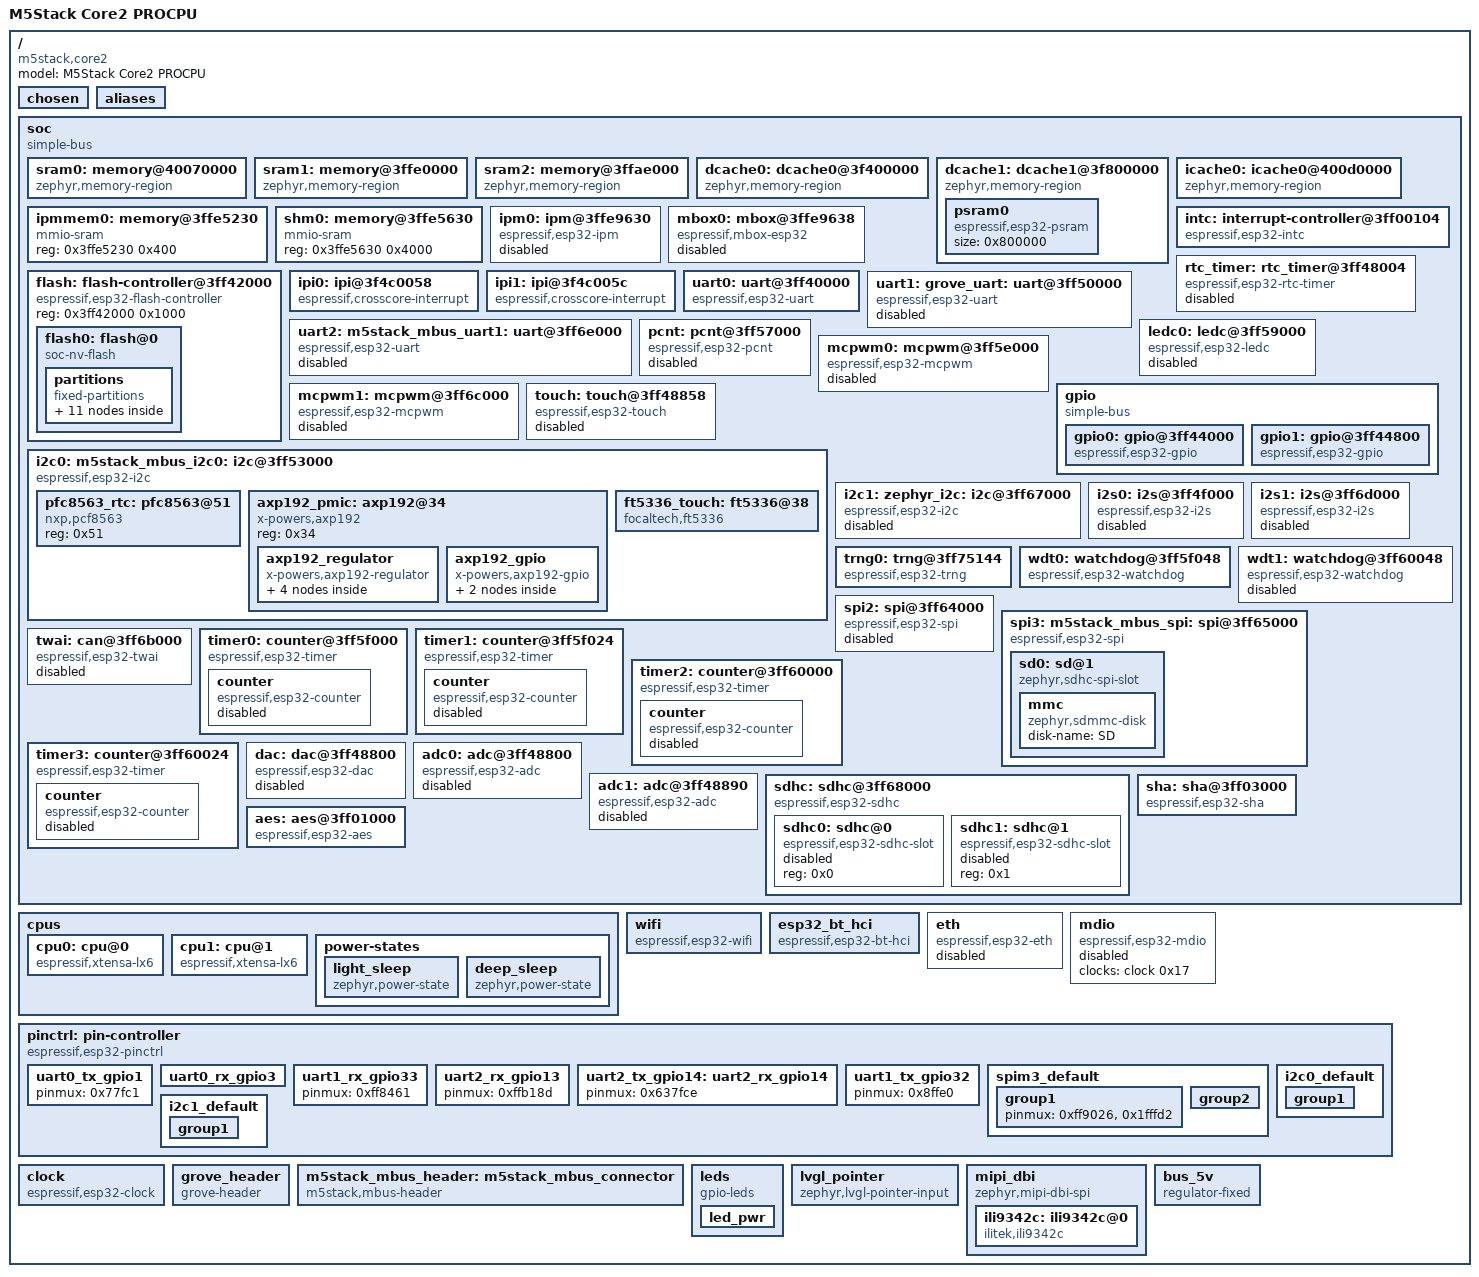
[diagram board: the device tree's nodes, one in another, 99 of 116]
/dts-v1/;

/* node '/' defined in zephyr/dts/common/skeleton.dtsi:9 */
/ {
	#address-cells = < 0x1 >;       /* in zephyr/dts/common/skeleton.dtsi:10 */
	#size-cells = < 0x1 >;          /* in zephyr/dts/common/skeleton.dtsi:11 */
	model = "M5Stack Core2 PROCPU"; /* in zephyr/boards/m5stack/m5stack_core2/m5stack_core2_procpu.dts:17 */
	compatible = "m5stack,core2";   /* in zephyr/boards/m5stack/m5stack_core2/m5stack_core2_procpu.dts:18 */

	/* node '/chosen' defined in zephyr/dts/common/skeleton.dtsi:13 */
	chosen {
		zephyr,canbus = &twai;                    /* in zephyr/dts/xtensa/espressif/esp32/esp32_common.dtsi:20 */
		zephyr,entropy = &trng0;                  /* in zephyr/dts/xtensa/espressif/esp32/esp32_common.dtsi:21 */
		zephyr,flash-controller = &flash;         /* in zephyr/dts/xtensa/espressif/esp32/esp32_common.dtsi:22 */
		zephyr,sram = &sram1;                     /* in zephyr/boards/m5stack/m5stack_core2/m5stack_core2_procpu.dts:31 */
		zephyr,console = &uart0;                  /* in zephyr/boards/m5stack/m5stack_core2/m5stack_core2_procpu.dts:32 */
		zephyr,shell-uart = &uart0;               /* in zephyr/boards/m5stack/m5stack_core2/m5stack_core2_procpu.dts:33 */
		zephyr,flash = &flash0;                   /* in zephyr/boards/m5stack/m5stack_core2/m5stack_core2_procpu.dts:34 */
		zephyr,display = &ili9342c;               /* in zephyr/boards/m5stack/m5stack_core2/m5stack_core2_procpu.dts:35 */
		zephyr,code-partition = &slot0_partition; /* in zephyr/boards/m5stack/m5stack_core2/m5stack_core2_procpu.dts:36 */
		zephyr,rtc = &pfc8563_rtc;                /* in zephyr/boards/m5stack/m5stack_core2/m5stack_core2_procpu.dts:37 */
		zephyr,bt-hci = &esp32_bt_hci;            /* in zephyr/boards/m5stack/m5stack_core2/m5stack_core2_procpu.dts:38 */
		zephyr,touch = &ft5336_touch;             /* in zephyr/boards/m5stack/m5stack_core2/m5stack_core2_procpu.dts:39 */
	};

	/* node '/aliases' defined in zephyr/dts/common/skeleton.dtsi:15 */
	aliases {
		pwr-led = &pwr_led; /* in zephyr/boards/m5stack/m5stack_core2/m5stack_core2_procpu.dts:21 */
		uart-0 = &uart0;    /* in zephyr/boards/m5stack/m5stack_core2/m5stack_core2_procpu.dts:22 */
		i2c-0 = &i2c0;      /* in zephyr/boards/m5stack/m5stack_core2/m5stack_core2_procpu.dts:23 */
		watchdog0 = &wdt0;  /* in zephyr/boards/m5stack/m5stack_core2/m5stack_core2_procpu.dts:24 */
		rtc = &pfc8563_rtc; /* in zephyr/boards/m5stack/m5stack_core2/m5stack_core2_procpu.dts:25 */
		led0 = &led_pwr;    /* in zephyr/boards/m5stack/m5stack_core2/m5stack_core2_procpu.dts:26 */
		sdhc0 = &sd0;       /* in zephyr/boards/m5stack/m5stack_core2/m5stack_core2_procpu.dts:27 */
	};

	/* node '/soc' defined in zephyr/dts/xtensa/xtensa.dtsi:10 */
	soc {
		#address-cells = < 0x1 >;  /* in zephyr/dts/xtensa/xtensa.dtsi:11 */
		#size-cells = < 0x1 >;     /* in zephyr/dts/xtensa/xtensa.dtsi:12 */
		compatible = "simple-bus"; /* in zephyr/dts/xtensa/xtensa.dtsi:13 */
		ranges;                    /* in zephyr/dts/xtensa/xtensa.dtsi:14 */

		/* node '/soc/memory@40070000' defined in zephyr/dts/xtensa/espressif/esp32/esp32_common.dtsi:106 */
		sram0: memory@40070000 {
			compatible = "zephyr,memory-region",
			             "mmio-sram";            /* in zephyr/dts/xtensa/espressif/esp32/esp32_common.dtsi:107 */
			reg = < 0x40070000 0x30000 >;        /* in zephyr/dts/xtensa/espressif/esp32/esp32_common.dtsi:108 */
			zephyr,memory-region = "SRAM0";      /* in zephyr/dts/xtensa/espressif/esp32/esp32_common.dtsi:109 */
		};

		/* node '/soc/memory@3ffe0000' defined in zephyr/dts/xtensa/espressif/esp32/esp32_common.dtsi:112 */
		sram1: memory@3ffe0000 {
			compatible = "zephyr,memory-region",
			             "mmio-sram";            /* in zephyr/dts/xtensa/espressif/esp32/esp32_common.dtsi:113 */
			reg = < 0x3ffe0000 0x20000 >;        /* in zephyr/dts/xtensa/espressif/esp32/esp32_common.dtsi:114 */
			zephyr,memory-region = "SRAM1";      /* in zephyr/dts/xtensa/espressif/esp32/esp32_common.dtsi:115 */
		};

		/* node '/soc/memory@3ffae000' defined in zephyr/dts/xtensa/espressif/esp32/esp32_common.dtsi:118 */
		sram2: memory@3ffae000 {
			compatible = "zephyr,memory-region",
			             "mmio-sram";            /* in zephyr/dts/xtensa/espressif/esp32/esp32_common.dtsi:119 */
			reg = < 0x3ffae000 0x32000 >;        /* in zephyr/dts/xtensa/espressif/esp32/esp32_common.dtsi:120 */
			zephyr,memory-region = "SRAM2";      /* in zephyr/dts/xtensa/espressif/esp32/esp32_common.dtsi:121 */
		};

		/* node '/soc/dcache0@3f400000' defined in zephyr/dts/xtensa/espressif/esp32/esp32_common.dtsi:124 */
		dcache0: dcache0@3f400000 {
			compatible = "zephyr,memory-region",
			             "mmio-sram";            /* in zephyr/dts/xtensa/espressif/esp32/esp32_common.dtsi:125 */
			reg = < 0x3f400000 0x400000 >;       /* in zephyr/dts/xtensa/espressif/esp32/esp32_common.dtsi:126 */
			zephyr,memory-region = "DCACHE0";    /* in zephyr/dts/xtensa/espressif/esp32/esp32_common.dtsi:127 */
		};

		/* node '/soc/dcache1@3f800000' defined in zephyr/dts/xtensa/espressif/esp32/esp32_common.dtsi:130 */
		dcache1: dcache1@3f800000 {
			compatible = "zephyr,memory-region",
			             "mmio-sram";            /* in zephyr/dts/xtensa/espressif/esp32/esp32_common.dtsi:131 */
			reg = < 0x3f800000 0x400000 >;       /* in zephyr/dts/xtensa/espressif/esp32/esp32_common.dtsi:132 */
			zephyr,memory-region = "DCACHE1";    /* in zephyr/dts/xtensa/espressif/esp32/esp32_common.dtsi:133 */

			/* node '/soc/dcache1@3f800000/psram0' defined in zephyr/dts/xtensa/espressif/esp32/esp32_common.dtsi:135 */
			psram0: psram0 {
				compatible = "espressif,esp32-psram"; /* in zephyr/dts/xtensa/espressif/esp32/esp32_common.dtsi:136 */
				size = < 0x800000 >;                  /* in zephyr/boards/m5stack/m5stack_core2/m5stack_core2_procpu.dts:91 */
			};
		};

		/* node '/soc/icache0@400d0000' defined in zephyr/dts/xtensa/espressif/esp32/esp32_common.dtsi:141 */
		icache0: icache0@400d0000 {
			compatible = "zephyr,memory-region",
			             "mmio-sram";            /* in zephyr/dts/xtensa/espressif/esp32/esp32_common.dtsi:142 */
			reg = < 0x400d0000 0xb30000 >;       /* in zephyr/dts/xtensa/espressif/esp32/esp32_common.dtsi:143 */
			zephyr,memory-region = "ICACHE0";    /* in zephyr/dts/xtensa/espressif/esp32/esp32_common.dtsi:144 */
		};

		/* node '/soc/memory@3ffe5230' defined in zephyr/dts/xtensa/espressif/esp32/esp32_common.dtsi:147 */
		ipmmem0: memory@3ffe5230 {
			compatible = "mmio-sram";   /* in zephyr/dts/xtensa/espressif/esp32/esp32_common.dtsi:148 */
			reg = < 0x3ffe5230 0x400 >; /* in zephyr/dts/xtensa/espressif/esp32/esp32_common.dtsi:149 */
			phandle = < 0x1 >;          /* in zephyr/dts/xtensa/espressif/esp32/esp32_common.dtsi:161 */
		};

		/* node '/soc/memory@3ffe5630' defined in zephyr/dts/xtensa/espressif/esp32/esp32_common.dtsi:152 */
		shm0: memory@3ffe5630 {
			compatible = "mmio-sram";    /* in zephyr/dts/xtensa/espressif/esp32/esp32_common.dtsi:153 */
			reg = < 0x3ffe5630 0x4000 >; /* in zephyr/dts/xtensa/espressif/esp32/esp32_common.dtsi:154 */
		};

		/* node '/soc/ipm@3ffe9630' defined in zephyr/dts/xtensa/espressif/esp32/esp32_common.dtsi:157 */
		ipm0: ipm@3ffe9630 {
			compatible = "espressif,esp32-ipm"; /* in zephyr/dts/xtensa/espressif/esp32/esp32_common.dtsi:158 */
			reg = < 0x3ffe9630 0x8 >;           /* in zephyr/dts/xtensa/espressif/esp32/esp32_common.dtsi:159 */
			status = "disabled";                /* in zephyr/dts/xtensa/espressif/esp32/esp32_common.dtsi:160 */
			shared-memory = < &ipmmem0 >;       /* in zephyr/dts/xtensa/espressif/esp32/esp32_common.dtsi:161 */
			shared-memory-size = < 0x400 >;     /* in zephyr/dts/xtensa/espressif/esp32/esp32_common.dtsi:162 */
			interrupts = < 0x18 0x0 0x0 >,
			             < 0x19 0x0 0x0 >;      /* in zephyr/dts/xtensa/espressif/esp32/esp32_common.dtsi:163 */
			interrupt-parent = < &intc >;       /* in zephyr/dts/xtensa/espressif/esp32/esp32_common.dtsi:165 */
		};

		/* node '/soc/mbox@3ffe9638' defined in zephyr/dts/xtensa/espressif/esp32/esp32_common.dtsi:168 */
		mbox0: mbox@3ffe9638 {
			compatible = "espressif,mbox-esp32"; /* in zephyr/dts/xtensa/espressif/esp32/esp32_common.dtsi:169 */
			reg = < 0x3ffe9638 0x8 >;            /* in zephyr/dts/xtensa/espressif/esp32/esp32_common.dtsi:170 */
			status = "disabled";                 /* in zephyr/dts/xtensa/espressif/esp32/esp32_common.dtsi:171 */
			shared-memory = < &ipmmem0 >;        /* in zephyr/dts/xtensa/espressif/esp32/esp32_common.dtsi:172 */
			shared-memory-size = < 0x400 >;      /* in zephyr/dts/xtensa/espressif/esp32/esp32_common.dtsi:173 */
			interrupts = < 0x18 0x0 0x0 >,
			             < 0x19 0x0 0x0 >;       /* in zephyr/dts/xtensa/espressif/esp32/esp32_common.dtsi:174 */
			interrupt-parent = < &intc >;        /* in zephyr/dts/xtensa/espressif/esp32/esp32_common.dtsi:176 */
			#mbox-cells = < 0x1 >;               /* in zephyr/dts/xtensa/espressif/esp32/esp32_common.dtsi:177 */
		};

		/* node '/soc/interrupt-controller@3ff00104' defined in zephyr/dts/xtensa/espressif/esp32/esp32_common.dtsi:180 */
		intc: interrupt-controller@3ff00104 {
			#interrupt-cells = < 0x3 >;          /* in zephyr/dts/xtensa/espressif/esp32/esp32_common.dtsi:181 */
			#address-cells = < 0x0 >;            /* in zephyr/dts/xtensa/espressif/esp32/esp32_common.dtsi:182 */
			compatible = "espressif,esp32-intc"; /* in zephyr/dts/xtensa/espressif/esp32/esp32_common.dtsi:183 */
			interrupt-controller;                /* in zephyr/dts/xtensa/espressif/esp32/esp32_common.dtsi:184 */
			reg = < 0x3ff00104 0x114 >;          /* in zephyr/dts/xtensa/espressif/esp32/esp32_common.dtsi:185 */
			status = "okay";                     /* in zephyr/dts/xtensa/espressif/esp32/esp32_common.dtsi:186 */
			phandle = < 0x2 >;                   /* in zephyr/dts/xtensa/espressif/esp32/esp32_common.dtsi:165 */
		};

		/* node '/soc/rtc_timer@3ff48004' defined in zephyr/dts/xtensa/espressif/esp32/esp32_common.dtsi:189 */
		rtc_timer: rtc_timer@3ff48004 {
			reg = < 0x3ff48004 0xc >;                 /* in zephyr/dts/xtensa/espressif/esp32/esp32_common.dtsi:190 */
			compatible = "espressif,esp32-rtc-timer"; /* in zephyr/dts/xtensa/espressif/esp32/esp32_common.dtsi:191 */
			clocks = < &clock 0x22 >;                 /* in zephyr/dts/xtensa/espressif/esp32/esp32_common.dtsi:192 */
			interrupts = < 0x2e 0x0 0x0 >;            /* in zephyr/dts/xtensa/espressif/esp32/esp32_common.dtsi:193 */
			interrupt-parent = < &intc >;             /* in zephyr/dts/xtensa/espressif/esp32/esp32_common.dtsi:194 */
			status = "disabled";                      /* in zephyr/dts/xtensa/espressif/esp32/esp32_common.dtsi:195 */
		};

		/* node '/soc/flash-controller@3ff42000' defined in zephyr/dts/xtensa/espressif/esp32/esp32_common.dtsi:198 */
		flash: flash-controller@3ff42000 {
			compatible = "espressif,esp32-flash-controller"; /* in zephyr/dts/xtensa/espressif/esp32/esp32_common.dtsi:199 */
			reg = < 0x3ff42000 0x1000 >;                     /* in zephyr/dts/xtensa/espressif/esp32/esp32_common.dtsi:200 */
			#address-cells = < 0x1 >;                        /* in zephyr/dts/xtensa/espressif/esp32/esp32_common.dtsi:201 */
			#size-cells = < 0x1 >;                           /* in zephyr/dts/xtensa/espressif/esp32/esp32_common.dtsi:202 */

			/* node '/soc/flash-controller@3ff42000/flash@0' defined in zephyr/dts/xtensa/espressif/esp32/esp32_common.dtsi:204 */
			flash0: flash@0 {
				compatible = "soc-nv-flash";   /* in zephyr/dts/xtensa/espressif/esp32/esp32_common.dtsi:205 */
				erase-block-size = < 0x1000 >; /* in zephyr/dts/xtensa/espressif/esp32/esp32_common.dtsi:206 */
				write-block-size = < 0x4 >;    /* in zephyr/dts/xtensa/espressif/esp32/esp32_common.dtsi:207 */
				reg = < 0x0 0x1000000 >;       /* in zephyr/boards/m5stack/m5stack_core2/m5stack_core2_procpu.dts:87 */

				/* node '/soc/flash-controller@3ff42000/flash@0/partitions' defined in zephyr/dts/vendor/espressif/partitions_0x1000_amp_4M.dtsi:8 */
				partitions {
					compatible = "fixed-partitions"; /* in zephyr/dts/vendor/espressif/partitions_0x1000_amp_4M.dtsi:9 */
					#address-cells = < 0x1 >;        /* in zephyr/dts/vendor/espressif/partitions_0x1000_amp_4M.dtsi:10 */
					#size-cells = < 0x1 >;           /* in zephyr/dts/vendor/espressif/partitions_0x1000_amp_4M.dtsi:11 */

					/* node '/soc/flash-controller@3ff42000/flash@0/partitions/partition@1000' defined in zephyr/dts/vendor/espressif/partitions_0x1000_amp_4M.dtsi:13 */
					boot_partition: partition@1000 {
						label = "mcuboot";       /* in zephyr/dts/vendor/espressif/partitions_0x1000_amp_4M.dtsi:14 */
						reg = < 0x1000 0xf000 >; /* in zephyr/dts/vendor/espressif/partitions_0x1000_amp_4M.dtsi:15 */
					};

					/* node '/soc/flash-controller@3ff42000/flash@0/partitions/partition@10000' defined in zephyr/dts/vendor/espressif/partitions_0x1000_amp_4M.dtsi:18 */
					sys_partition: partition@10000 {
						label = "sys";             /* in zephyr/dts/vendor/espressif/partitions_0x1000_amp_4M.dtsi:19 */
						reg = < 0x10000 0x10000 >; /* in zephyr/dts/vendor/espressif/partitions_0x1000_amp_4M.dtsi:20 */
					};

					/* node '/soc/flash-controller@3ff42000/flash@0/partitions/partition@20000' defined in zephyr/dts/vendor/espressif/partitions_0x1000_amp_4M.dtsi:23 */
					slot0_partition: partition@20000 {
						label = "image-0";          /* in zephyr/dts/vendor/espressif/partitions_0x1000_amp_4M.dtsi:24 */
						reg = < 0x20000 0x150000 >; /* in zephyr/dts/vendor/espressif/partitions_0x1000_amp_4M.dtsi:25 */
					};

					/* node '/soc/flash-controller@3ff42000/flash@0/partitions/partition@170000' defined in zephyr/dts/vendor/espressif/partitions_0x1000_amp_4M.dtsi:28 */
					slot1_partition: partition@170000 {
						label = "image-1";           /* in zephyr/dts/vendor/espressif/partitions_0x1000_amp_4M.dtsi:29 */
						reg = < 0x170000 0x150000 >; /* in zephyr/dts/vendor/espressif/partitions_0x1000_amp_4M.dtsi:30 */
					};

					/* node '/soc/flash-controller@3ff42000/flash@0/partitions/partition@2c0000' defined in zephyr/dts/vendor/espressif/partitions_0x1000_amp_4M.dtsi:33 */
					slot0_appcpu_partition: partition@2c0000 {
						label = "image-0-appcpu";   /* in zephyr/dts/vendor/espressif/partitions_0x1000_amp_4M.dtsi:34 */
						reg = < 0x2c0000 0x70000 >; /* in zephyr/dts/vendor/espressif/partitions_0x1000_amp_4M.dtsi:35 */
					};

					/* node '/soc/flash-controller@3ff42000/flash@0/partitions/partition@330000' defined in zephyr/dts/vendor/espressif/partitions_0x1000_amp_4M.dtsi:38 */
					slot1_appcpu_partition: partition@330000 {
						label = "image-1-appcpu";   /* in zephyr/dts/vendor/espressif/partitions_0x1000_amp_4M.dtsi:39 */
						reg = < 0x330000 0x70000 >; /* in zephyr/dts/vendor/espressif/partitions_0x1000_amp_4M.dtsi:40 */
					};

					/* node '/soc/flash-controller@3ff42000/flash@0/partitions/partition@3a0000' defined in zephyr/dts/vendor/espressif/partitions_0x1000_amp_4M.dtsi:43 */
					slot0_lpcore_partition: partition@3a0000 {
						label = "image-0-lpcore";  /* in zephyr/dts/vendor/espressif/partitions_0x1000_amp_4M.dtsi:44 */
						reg = < 0x3a0000 0x8000 >; /* in zephyr/dts/vendor/espressif/partitions_0x1000_amp_4M.dtsi:45 */
					};

					/* node '/soc/flash-controller@3ff42000/flash@0/partitions/partition@3a8000' defined in zephyr/dts/vendor/espressif/partitions_0x1000_amp_4M.dtsi:48 */
					slot1_lpcore_partition: partition@3a8000 {
						label = "image-1-lpcore";  /* in zephyr/dts/vendor/espressif/partitions_0x1000_amp_4M.dtsi:49 */
						reg = < 0x3a8000 0x8000 >; /* in zephyr/dts/vendor/espressif/partitions_0x1000_amp_4M.dtsi:50 */
					};

					/* node '/soc/flash-controller@3ff42000/flash@0/partitions/partition@3b0000' defined in zephyr/dts/vendor/espressif/partitions_0x1000_amp_4M.dtsi:53 */
					storage_partition: partition@3b0000 {
						label = "storage";          /* in zephyr/dts/vendor/espressif/partitions_0x1000_amp_4M.dtsi:54 */
						reg = < 0x3b0000 0x30000 >; /* in zephyr/dts/vendor/espressif/partitions_0x1000_amp_4M.dtsi:55 */
					};

					/* node '/soc/flash-controller@3ff42000/flash@0/partitions/partition@3e0000' defined in zephyr/dts/vendor/espressif/partitions_0x1000_amp_4M.dtsi:58 */
					scratch_partition: partition@3e0000 {
						label = "image-scratch";    /* in zephyr/dts/vendor/espressif/partitions_0x1000_amp_4M.dtsi:59 */
						reg = < 0x3e0000 0x1f000 >; /* in zephyr/dts/vendor/espressif/partitions_0x1000_amp_4M.dtsi:60 */
					};

					/* node '/soc/flash-controller@3ff42000/flash@0/partitions/partition@3ff000' defined in zephyr/dts/vendor/espressif/partitions_0x1000_amp_4M.dtsi:63 */
					coredump_partition: partition@3ff000 {
						label = "coredump";        /* in zephyr/dts/vendor/espressif/partitions_0x1000_amp_4M.dtsi:64 */
						reg = < 0x3ff000 0x1000 >; /* in zephyr/dts/vendor/espressif/partitions_0x1000_amp_4M.dtsi:65 */
					};
				};
			};
		};

		/* node '/soc/ipi@3f4c0058' defined in zephyr/dts/xtensa/espressif/esp32/esp32_common.dtsi:212 */
		ipi0: ipi@3f4c0058 {
			compatible = "espressif,crosscore-interrupt"; /* in zephyr/dts/xtensa/espressif/esp32/esp32_common.dtsi:213 */
			reg = < 0x3f4c0058 0x4 >;                     /* in zephyr/dts/xtensa/espressif/esp32/esp32_common.dtsi:214 */
			interrupts = < 0x18 0x0 0x0 >;                /* in zephyr/dts/xtensa/espressif/esp32/esp32_common.dtsi:215 */
			interrupt-parent = < &intc >;                 /* in zephyr/dts/xtensa/espressif/esp32/esp32_common.dtsi:216 */
		};

		/* node '/soc/ipi@3f4c005c' defined in zephyr/dts/xtensa/espressif/esp32/esp32_common.dtsi:219 */
		ipi1: ipi@3f4c005c {
			compatible = "espressif,crosscore-interrupt"; /* in zephyr/dts/xtensa/espressif/esp32/esp32_common.dtsi:220 */
			reg = < 0x3f4c005c 0x4 >;                     /* in zephyr/dts/xtensa/espressif/esp32/esp32_common.dtsi:221 */
			interrupts = < 0x19 0x0 0x0 >;                /* in zephyr/dts/xtensa/espressif/esp32/esp32_common.dtsi:222 */
			interrupt-parent = < &intc >;                 /* in zephyr/dts/xtensa/espressif/esp32/esp32_common.dtsi:223 */
		};

		/* node '/soc/uart@3ff40000' defined in zephyr/dts/xtensa/espressif/esp32/esp32_common.dtsi:226 */
		uart0: uart@3ff40000 {
			compatible = "espressif,esp32-uart";             /* in zephyr/dts/xtensa/espressif/esp32/esp32_common.dtsi:227 */
			reg = < 0x3ff40000 0x400 >;                      /* in zephyr/dts/xtensa/espressif/esp32/esp32_common.dtsi:228 */
			interrupts = < 0x22 0x0 0x0 >;                   /* in zephyr/dts/xtensa/espressif/esp32/esp32_common.dtsi:229 */
			interrupt-parent = < &intc >;                    /* in zephyr/dts/xtensa/espressif/esp32/esp32_common.dtsi:230 */
			clocks = < &clock 0x1 >;                         /* in zephyr/dts/xtensa/espressif/esp32/esp32_common.dtsi:231 */
			status = "okay";                                 /* in zephyr/boards/m5stack/m5stack_core2/m5stack_core2_procpu.dts:95 */
			current-speed = < 0x1c200 >;                     /* in zephyr/boards/m5stack/m5stack_core2/m5stack_core2_procpu.dts:96 */
			pinctrl-0 = < &uart0_tx_gpio1 &uart0_rx_gpio3 >; /* in zephyr/boards/m5stack/m5stack_core2/m5stack_core2_procpu.dts:97 */
			pinctrl-names = "default";                       /* in zephyr/boards/m5stack/m5stack_core2/m5stack_core2_procpu.dts:98 */
		};

		/* node '/soc/uart@3ff50000' defined in zephyr/dts/xtensa/espressif/esp32/esp32_common.dtsi:235 */
		uart1: grove_uart: m5stack_mbus_uart0: uart@3ff50000 {
			compatible = "espressif,esp32-uart";               /* in zephyr/dts/xtensa/espressif/esp32/esp32_common.dtsi:236 */
			reg = < 0x3ff50000 0x400 >;                        /* in zephyr/dts/xtensa/espressif/esp32/esp32_common.dtsi:237 */
			interrupts = < 0x23 0x0 0x0 >;                     /* in zephyr/dts/xtensa/espressif/esp32/esp32_common.dtsi:238 */
			interrupt-parent = < &intc >;                      /* in zephyr/dts/xtensa/espressif/esp32/esp32_common.dtsi:239 */
			clocks = < &clock 0x2 >;                           /* in zephyr/dts/xtensa/espressif/esp32/esp32_common.dtsi:240 */
			status = "disabled";                               /* in zephyr/boards/m5stack/m5stack_core2/m5stack_core2_procpu.dts:102 */
			current-speed = < 0x1c200 >;                       /* in zephyr/boards/m5stack/m5stack_core2/m5stack_core2_procpu.dts:103 */
			pinctrl-0 = < &uart1_rx_gpio33 &uart1_tx_gpio32 >; /* in zephyr/boards/m5stack/m5stack_core2/m5stack_core2_procpu.dts:104 */
			pinctrl-names = "default";                         /* in zephyr/boards/m5stack/m5stack_core2/m5stack_core2_procpu.dts:105 */
		};

		/* node '/soc/uart@3ff6e000' defined in zephyr/dts/xtensa/espressif/esp32/esp32_common.dtsi:244 */
		uart2: m5stack_mbus_uart1: uart@3ff6e000 {
			compatible = "espressif,esp32-uart"; /* in zephyr/dts/xtensa/espressif/esp32/esp32_common.dtsi:245 */
			reg = < 0x3ff6e000 0x400 >;          /* in zephyr/dts/xtensa/espressif/esp32/esp32_common.dtsi:246 */
			interrupts = < 0x24 0x0 0x0 >;       /* in zephyr/dts/xtensa/espressif/esp32/esp32_common.dtsi:247 */
			interrupt-parent = < &intc >;        /* in zephyr/dts/xtensa/espressif/esp32/esp32_common.dtsi:248 */
			clocks = < &clock 0x3 >;             /* in zephyr/dts/xtensa/espressif/esp32/esp32_common.dtsi:249 */
			status = "disabled";                 /* in zephyr/dts/xtensa/espressif/esp32/esp32_common.dtsi:250 */
		};

		/* node '/soc/pcnt@3ff57000' defined in zephyr/dts/xtensa/espressif/esp32/esp32_common.dtsi:253 */
		pcnt: pcnt@3ff57000 {
			compatible = "espressif,esp32-pcnt"; /* in zephyr/dts/xtensa/espressif/esp32/esp32_common.dtsi:254 */
			reg = < 0x3ff57000 0x1000 >;         /* in zephyr/dts/xtensa/espressif/esp32/esp32_common.dtsi:255 */
			interrupts = < 0x30 0x0 0x0 >;       /* in zephyr/dts/xtensa/espressif/esp32/esp32_common.dtsi:256 */
			interrupt-parent = < &intc >;        /* in zephyr/dts/xtensa/espressif/esp32/esp32_common.dtsi:257 */
			clocks = < &clock 0xf >;             /* in zephyr/dts/xtensa/espressif/esp32/esp32_common.dtsi:258 */
			status = "disabled";                 /* in zephyr/dts/xtensa/espressif/esp32/esp32_common.dtsi:259 */
		};

		/* node '/soc/ledc@3ff59000' defined in zephyr/dts/xtensa/espressif/esp32/esp32_common.dtsi:262 */
		ledc0: ledc@3ff59000 {
			compatible = "espressif,esp32-ledc"; /* in zephyr/dts/xtensa/espressif/esp32/esp32_common.dtsi:263 */
			#pwm-cells = < 0x3 >;                /* in zephyr/dts/xtensa/espressif/esp32/esp32_common.dtsi:264 */
			reg = < 0x3ff59000 0x800 >;          /* in zephyr/dts/xtensa/espressif/esp32/esp32_common.dtsi:265 */
			clocks = < &clock 0x0 >;             /* in zephyr/dts/xtensa/espressif/esp32/esp32_common.dtsi:266 */
			status = "disabled";                 /* in zephyr/dts/xtensa/espressif/esp32/esp32_common.dtsi:267 */
		};

		/* node '/soc/mcpwm@3ff5e000' defined in zephyr/dts/xtensa/espressif/esp32/esp32_common.dtsi:270 */
		mcpwm0: mcpwm@3ff5e000 {
			compatible = "espressif,esp32-mcpwm"; /* in zephyr/dts/xtensa/espressif/esp32/esp32_common.dtsi:271 */
			reg = < 0x3ff5e000 0x1000 >;          /* in zephyr/dts/xtensa/espressif/esp32/esp32_common.dtsi:272 */
			interrupts = < 0x27 0x0 0x0 >;        /* in zephyr/dts/xtensa/espressif/esp32/esp32_common.dtsi:273 */
			interrupt-parent = < &intc >;         /* in zephyr/dts/xtensa/espressif/esp32/esp32_common.dtsi:274 */
			clocks = < &clock 0xa >;              /* in zephyr/dts/xtensa/espressif/esp32/esp32_common.dtsi:275 */
			#pwm-cells = < 0x3 >;                 /* in zephyr/dts/xtensa/espressif/esp32/esp32_common.dtsi:276 */
			status = "disabled";                  /* in zephyr/dts/xtensa/espressif/esp32/esp32_common.dtsi:277 */
		};

		/* node '/soc/mcpwm@3ff6c000' defined in zephyr/dts/xtensa/espressif/esp32/esp32_common.dtsi:280 */
		mcpwm1: mcpwm@3ff6c000 {
			compatible = "espressif,esp32-mcpwm"; /* in zephyr/dts/xtensa/espressif/esp32/esp32_common.dtsi:281 */
			reg = < 0x3ff6c000 0x1000 >;          /* in zephyr/dts/xtensa/espressif/esp32/esp32_common.dtsi:282 */
			interrupts = < 0x28 0x0 0x0 >;        /* in zephyr/dts/xtensa/espressif/esp32/esp32_common.dtsi:283 */
			interrupt-parent = < &intc >;         /* in zephyr/dts/xtensa/espressif/esp32/esp32_common.dtsi:284 */
			clocks = < &clock 0xb >;              /* in zephyr/dts/xtensa/espressif/esp32/esp32_common.dtsi:285 */
			#pwm-cells = < 0x3 >;                 /* in zephyr/dts/xtensa/espressif/esp32/esp32_common.dtsi:286 */
			status = "disabled";                  /* in zephyr/dts/xtensa/espressif/esp32/esp32_common.dtsi:287 */
		};

		/* node '/soc/gpio' defined in zephyr/dts/xtensa/espressif/esp32/esp32_common.dtsi:290 */
		gpio: gpio {
			compatible = "simple-bus";                                     /* in zephyr/dts/xtensa/espressif/esp32/esp32_common.dtsi:291 */
			gpio-map-mask = < 0xffffffe0 0xffffffc0 >;                     /* in zephyr/dts/xtensa/espressif/esp32/esp32_common.dtsi:292 */
			gpio-map-pass-thru = < 0x1f 0x3f >;                            /* in zephyr/dts/xtensa/espressif/esp32/esp32_common.dtsi:293 */
			gpio-map = < 0x0 0x0 &gpio0 0x0 0x0 0x20 0x0 &gpio1 0x0 0x0 >; /* in zephyr/dts/xtensa/espressif/esp32/esp32_common.dtsi:294 */
			#gpio-cells = < 0x2 >;                                         /* in zephyr/dts/xtensa/espressif/esp32/esp32_common.dtsi:296 */
			#address-cells = < 0x1 >;                                      /* in zephyr/dts/xtensa/espressif/esp32/esp32_common.dtsi:297 */
			#size-cells = < 0x1 >;                                         /* in zephyr/dts/xtensa/espressif/esp32/esp32_common.dtsi:298 */
			ranges;                                                        /* in zephyr/dts/xtensa/espressif/esp32/esp32_common.dtsi:299 */

			/* node '/soc/gpio/gpio@3ff44000' defined in zephyr/dts/xtensa/espressif/esp32/esp32_common.dtsi:301 */
			gpio0: gpio@3ff44000 {
				compatible = "espressif,esp32-gpio"; /* in zephyr/dts/xtensa/espressif/esp32/esp32_common.dtsi:302 */
				gpio-controller;                     /* in zephyr/dts/xtensa/espressif/esp32/esp32_common.dtsi:303 */
				#gpio-cells = < 0x2 >;               /* in zephyr/dts/xtensa/espressif/esp32/esp32_common.dtsi:304 */
				reg = < 0x3ff44000 0x800 >;          /* in zephyr/dts/xtensa/espressif/esp32/esp32_common.dtsi:305 */
				interrupts = < 0x16 0x0 0x0 >;       /* in zephyr/dts/xtensa/espressif/esp32/esp32_common.dtsi:306 */
				interrupt-parent = < &intc >;        /* in zephyr/dts/xtensa/espressif/esp32/esp32_common.dtsi:307 */
				ngpios = < 0x20 >;                   /* in zephyr/dts/xtensa/espressif/esp32/esp32_common.dtsi:313 */
				gpio-reserved-ranges = < 0x14 0x1 >,
				                       < 0x18 0x1 >,
				                       < 0x1c 0x4 >; /* in zephyr/dts/xtensa/espressif/esp32/esp32_d0wd_v3.dtsi:11 */
				status = "okay";                     /* in zephyr/boards/m5stack/m5stack_core2/m5stack_core2_procpu.dts:109 */
				phandle = < 0x8 >;                   /* in zephyr/dts/xtensa/espressif/esp32/esp32_common.dtsi:294 */
			};

			/* node '/soc/gpio/gpio@3ff44800' defined in zephyr/dts/xtensa/espressif/esp32/esp32_common.dtsi:316 */
			gpio1: gpio@3ff44800 {
				compatible = "espressif,esp32-gpio"; /* in zephyr/dts/xtensa/espressif/esp32/esp32_common.dtsi:317 */
				gpio-controller;                     /* in zephyr/dts/xtensa/espressif/esp32/esp32_common.dtsi:318 */
				#gpio-cells = < 0x2 >;               /* in zephyr/dts/xtensa/espressif/esp32/esp32_common.dtsi:319 */
				reg = < 0x3ff44800 0x800 >;          /* in zephyr/dts/xtensa/espressif/esp32/esp32_common.dtsi:320 */
				interrupts = < 0x16 0x0 0x0 >;       /* in zephyr/dts/xtensa/espressif/esp32/esp32_common.dtsi:321 */
				interrupt-parent = < &intc >;        /* in zephyr/dts/xtensa/espressif/esp32/esp32_common.dtsi:322 */
				ngpios = < 0x8 >;                    /* in zephyr/dts/xtensa/espressif/esp32/esp32_common.dtsi:323 */
				status = "okay";                     /* in zephyr/boards/m5stack/m5stack_core2/m5stack_core2_procpu.dts:113 */
				phandle = < 0x9 >;                   /* in zephyr/dts/xtensa/espressif/esp32/esp32_common.dtsi:294 */
			};
		};

		/* node '/soc/touch@3ff48858' defined in zephyr/dts/xtensa/espressif/esp32/esp32_common.dtsi:327 */
		touch: touch@3ff48858 {
			compatible = "espressif,esp32-touch"; /* in zephyr/dts/xtensa/espressif/esp32/esp32_common.dtsi:328 */
			reg = < 0x3ff48858 0x38 >;            /* in zephyr/dts/xtensa/espressif/esp32/esp32_common.dtsi:329 */
			interrupts = < 0x2e 0x0 0x0 >;        /* in zephyr/dts/xtensa/espressif/esp32/esp32_common.dtsi:330 */
			interrupt-parent = < &intc >;         /* in zephyr/dts/xtensa/espressif/esp32/esp32_common.dtsi:331 */
			status = "disabled";                  /* in zephyr/dts/xtensa/espressif/esp32/esp32_common.dtsi:332 */
		};

		/* node '/soc/i2c@3ff53000' defined in zephyr/dts/xtensa/espressif/esp32/esp32_common.dtsi:335 */
		i2c0: m5stack_mbus_i2c0: i2c@3ff53000 {
			compatible = "espressif,esp32-i2c"; /* in zephyr/dts/xtensa/espressif/esp32/esp32_common.dtsi:336 */
			#address-cells = < 0x1 >;           /* in zephyr/dts/xtensa/espressif/esp32/esp32_common.dtsi:337 */
			#size-cells = < 0x0 >;              /* in zephyr/dts/xtensa/espressif/esp32/esp32_common.dtsi:338 */
			reg = < 0x3ff53000 0x1000 >;        /* in zephyr/dts/xtensa/espressif/esp32/esp32_common.dtsi:339 */
			interrupts = < 0x31 0x0 0x0 >;      /* in zephyr/dts/xtensa/espressif/esp32/esp32_common.dtsi:340 */
			interrupt-parent = < &intc >;       /* in zephyr/dts/xtensa/espressif/esp32/esp32_common.dtsi:341 */
			clocks = < &clock 0x4 >;            /* in zephyr/dts/xtensa/espressif/esp32/esp32_common.dtsi:342 */
			status = "okay";                    /* in zephyr/boards/m5stack/m5stack_core2/m5stack_core2_procpu.dts:117 */
			clock-frequency = < 0x61a80 >;      /* in zephyr/boards/m5stack/m5stack_core2/m5stack_core2_procpu.dts:118 */
			sda-gpios = < &gpio0 0x15 0x6 >;    /* in zephyr/boards/m5stack/m5stack_core2/m5stack_core2_procpu.dts:119 */
			scl-gpios = < &gpio0 0x16 0x6 >;    /* in zephyr/boards/m5stack/m5stack_core2/m5stack_core2_procpu.dts:120 */
			pinctrl-0 = < &i2c0_default >;      /* in zephyr/boards/m5stack/m5stack_core2/m5stack_core2_procpu.dts:121 */
			scl-timeout-us = < 0x0 >;           /* in zephyr/boards/m5stack/m5stack_core2/m5stack_core2_procpu.dts:122 */
			pinctrl-names = "default";          /* in zephyr/boards/m5stack/m5stack_core2/m5stack_core2_procpu.dts:123 */

			/* node '/soc/i2c@3ff53000/pfc8563@51' defined in zephyr/boards/m5stack/m5stack_core2/m5stack_core2_procpu.dts:125 */
			pfc8563_rtc: pfc8563@51 {
				compatible = "nxp,pcf8563"; /* in zephyr/boards/m5stack/m5stack_core2/m5stack_core2_procpu.dts:126 */
				reg = < 0x51 >;             /* in zephyr/boards/m5stack/m5stack_core2/m5stack_core2_procpu.dts:127 */
				status = "okay";            /* in zephyr/boards/m5stack/m5stack_core2/m5stack_core2_procpu.dts:128 */
			};

			/* node '/soc/i2c@3ff53000/axp192@34' defined in zephyr/boards/m5stack/m5stack_core2/m5stack_core2_procpu.dts:131 */
			axp192_pmic: axp192@34 {
				compatible = "x-powers,axp192"; /* in zephyr/boards/m5stack/m5stack_core2/m5stack_core2_procpu.dts:132 */
				reg = < 0x34 >;                 /* in zephyr/boards/m5stack/m5stack_core2/m5stack_core2_procpu.dts:133 */
				status = "okay";                /* in zephyr/boards/m5stack/m5stack_core2/m5stack_core2_procpu.dts:134 */

				/* node '/soc/i2c@3ff53000/axp192@34/axp192_regulator' defined in zephyr/boards/m5stack/m5stack_core2/m5stack_core2_procpu.dts:136 */
				axp192_regulator: axp192_regulator {
					compatible = "x-powers,axp192-regulator"; /* in zephyr/boards/m5stack/m5stack_core2/m5stack_core2_procpu.dts:137 */
					status = "okay";                          /* in zephyr/boards/m5stack/m5stack_core2/m5stack_core2_procpu.dts:138 */

					/* node '/soc/i2c@3ff53000/axp192@34/axp192_regulator/DCDC1' defined in zephyr/boards/m5stack/m5stack_core2/m5stack_core2_procpu.dts:140 */
					vdd_mcu: DCDC1 {
						regulator-init-microvolt = < 0x331df0 >; /* in zephyr/boards/m5stack/m5stack_core2/m5stack_core2_procpu.dts:141 */
						regulator-min-microvolt = < 0x30d400 >;  /* in zephyr/boards/m5stack/m5stack_core2/m5stack_core2_procpu.dts:142 */
						regulator-max-microvolt = < 0x33e140 >;  /* in zephyr/boards/m5stack/m5stack_core2/m5stack_core2_procpu.dts:143 */
						regulator-initial-mode = < 0x0 >;        /* in zephyr/boards/m5stack/m5stack_core2/m5stack_core2_procpu.dts:144 */
						regulator-boot-on;                       /* in zephyr/boards/m5stack/m5stack_core2/m5stack_core2_procpu.dts:145 */
						regulator-always-on;                     /* in zephyr/boards/m5stack/m5stack_core2/m5stack_core2_procpu.dts:146 */
					};

					/* node '/soc/i2c@3ff53000/axp192@34/axp192_regulator/DCDC3' defined in zephyr/boards/m5stack/m5stack_core2/m5stack_core2_procpu.dts:149 */
					lcd_bg: DCDC3 {
						regulator-init-microvolt = < 0x2ab980 >; /* in zephyr/boards/m5stack/m5stack_core2/m5stack_core2_procpu.dts:150 */
						regulator-min-microvolt = < 0x2625a0 >;  /* in zephyr/boards/m5stack/m5stack_core2/m5stack_core2_procpu.dts:151 */
						regulator-max-microvolt = < 0x325aa0 >;  /* in zephyr/boards/m5stack/m5stack_core2/m5stack_core2_procpu.dts:152 */
						regulator-boot-on;                       /* in zephyr/boards/m5stack/m5stack_core2/m5stack_core2_procpu.dts:153 */
						phandle = < 0x12 >;                      /* in zephyr/boards/m5stack/m5stack_core2/m5stack_core2_procpu.dts:70 */
					};

					/* node '/soc/i2c@3ff53000/axp192@34/axp192_regulator/LDO2' defined in zephyr/boards/m5stack/m5stack_core2/m5stack_core2_procpu.dts:156 */
					v_peri: LDO2 {
						regulator-init-microvolt = < 0x325aa0 >; /* in zephyr/boards/m5stack/m5stack_core2/m5stack_core2_procpu.dts:157 */
						regulator-min-microvolt = < 0x30d400 >;  /* in zephyr/boards/m5stack/m5stack_core2/m5stack_core2_procpu.dts:158 */
						regulator-max-microvolt = < 0x325aa0 >;  /* in zephyr/boards/m5stack/m5stack_core2/m5stack_core2_procpu.dts:159 */
						regulator-boot-on;                       /* in zephyr/boards/m5stack/m5stack_core2/m5stack_core2_procpu.dts:160 */
					};

					/* node '/soc/i2c@3ff53000/axp192@34/axp192_regulator/LDO3' defined in zephyr/boards/m5stack/m5stack_core2/m5stack_core2_procpu.dts:163 */
					vib_motor: LDO3 {
						regulator-init-microvolt = < 0x2ab980 >; /* in zephyr/boards/m5stack/m5stack_core2/m5stack_core2_procpu.dts:164 */
					};
				};

				/* node '/soc/i2c@3ff53000/axp192@34/axp192_gpio' defined in zephyr/boards/m5stack/m5stack_core2/m5stack_core2_procpu.dts:168 */
				axp192_gpio: axp192_gpio {
					compatible = "x-powers,axp192-gpio"; /* in zephyr/boards/m5stack/m5stack_core2/m5stack_core2_procpu.dts:169 */
					gpio-controller;                     /* in zephyr/boards/m5stack/m5stack_core2/m5stack_core2_procpu.dts:170 */
					#gpio-cells = < 0x2 >;               /* in zephyr/boards/m5stack/m5stack_core2/m5stack_core2_procpu.dts:171 */
					ngpios = < 0x6 >;                    /* in zephyr/boards/m5stack/m5stack_core2/m5stack_core2_procpu.dts:172 */
					status = "okay";                     /* in zephyr/boards/m5stack/m5stack_core2/m5stack_core2_procpu.dts:173 */
					phandle = < 0xf >;                   /* in zephyr/boards/m5stack/m5stack_core2/m5stack_core2_procpu.dts:46 */

					/* node '/soc/i2c@3ff53000/axp192@34/axp192_gpio/axp192_gpio1' defined in zephyr/boards/m5stack/m5stack_core2/m5stack_core2_procpu.dts:175 */
					pwr_led: axp192_gpio1 {
						gpio-hog;              /* in zephyr/boards/m5stack/m5stack_core2/m5stack_core2_procpu.dts:176 */
						gpios = < 0x1 0x7 >;   /* in zephyr/boards/m5stack/m5stack_core2/m5stack_core2_procpu.dts:177 */
						output-high;           /* in zephyr/boards/m5stack/m5stack_core2/m5stack_core2_procpu.dts:178 */
						line-name = "pwr-led"; /* in zephyr/boards/m5stack/m5stack_core2/m5stack_core2_procpu.dts:179 */
					};

					/* node '/soc/i2c@3ff53000/axp192@34/axp192_gpio/axp192_gpio0' defined in zephyr/boards/m5stack/m5stack_core2/m5stack_core2_procpu.dts:182 */
					bus_pwr_en: axp192_gpio0 {
						gpio-hog;                 /* in zephyr/boards/m5stack/m5stack_core2/m5stack_core2_procpu.dts:183 */
						gpios = < 0x0 0x0 >;      /* in zephyr/boards/m5stack/m5stack_core2/m5stack_core2_procpu.dts:184 */
						output-high;              /* in zephyr/boards/m5stack/m5stack_core2/m5stack_core2_procpu.dts:185 */
						line-name = "bus_pwr_en"; /* in zephyr/boards/m5stack/m5stack_core2/m5stack_core2_procpu.dts:186 */
					};
				};
			};

			/* node '/soc/i2c@3ff53000/ft5336@38' defined in zephyr/boards/m5stack/m5stack_core2/m5stack_core2_procpu.dts:191 */
			ft5336_touch: ft5336@38 {
				compatible = "focaltech,ft5336"; /* in zephyr/boards/m5stack/m5stack_core2/m5stack_core2_procpu.dts:192 */
				reg = < 0x38 >;                  /* in zephyr/boards/m5stack/m5stack_core2/m5stack_core2_procpu.dts:193 */
				int-gpios = < &gpio1 0x7 0x1 >;  /* in zephyr/boards/m5stack/m5stack_core2/m5stack_core2_procpu.dts:194 */
				phandle = < 0x10 >;              /* in zephyr/boards/m5stack/m5stack_core2/m5stack_core2_procpu.dts:53 */
			};
		};

		/* node '/soc/i2c@3ff67000' defined in zephyr/dts/xtensa/espressif/esp32/esp32_common.dtsi:346 */
		i2c1: zephyr_i2c: m5stack_mbus_i2c1: i2c@3ff67000 {
			compatible = "espressif,esp32-i2c"; /* in zephyr/dts/xtensa/espressif/esp32/esp32_common.dtsi:347 */
			#address-cells = < 0x1 >;           /* in zephyr/dts/xtensa/espressif/esp32/esp32_common.dtsi:348 */
			#size-cells = < 0x0 >;              /* in zephyr/dts/xtensa/espressif/esp32/esp32_common.dtsi:349 */
			reg = < 0x3ff67000 0x1000 >;        /* in zephyr/dts/xtensa/espressif/esp32/esp32_common.dtsi:350 */
			interrupts = < 0x32 0x0 0x0 >;      /* in zephyr/dts/xtensa/espressif/esp32/esp32_common.dtsi:351 */
			interrupt-parent = < &intc >;       /* in zephyr/dts/xtensa/espressif/esp32/esp32_common.dtsi:352 */
			clocks = < &clock 0x5 >;            /* in zephyr/dts/xtensa/espressif/esp32/esp32_common.dtsi:353 */
			status = "disabled";                /* in zephyr/boards/m5stack/m5stack_core2/m5stack_core2_procpu.dts:199 */
			clock-frequency = < 0x186a0 >;      /* in zephyr/boards/m5stack/m5stack_core2/m5stack_core2_procpu.dts:200 */
			sda-gpios = < &gpio1 0x0 0x6 >;     /* in zephyr/boards/m5stack/m5stack_core2/m5stack_core2_procpu.dts:201 */
			scl-gpios = < &gpio1 0x1 0x6 >;     /* in zephyr/boards/m5stack/m5stack_core2/m5stack_core2_procpu.dts:202 */
			pinctrl-0 = < &i2c1_default >;      /* in zephyr/boards/m5stack/m5stack_core2/m5stack_core2_procpu.dts:203 */
			pinctrl-names = "default";          /* in zephyr/boards/m5stack/m5stack_core2/m5stack_core2_procpu.dts:204 */
		};

		/* node '/soc/i2s@3ff4f000' defined in zephyr/dts/xtensa/espressif/esp32/esp32_common.dtsi:357 */
		i2s0: i2s@3ff4f000 {
			compatible = "espressif,esp32-i2s"; /* in zephyr/dts/xtensa/espressif/esp32/esp32_common.dtsi:358 */
			#address-cells = < 0x1 >;           /* in zephyr/dts/xtensa/espressif/esp32/esp32_common.dtsi:359 */
			#size-cells = < 0x0 >;              /* in zephyr/dts/xtensa/espressif/esp32/esp32_common.dtsi:360 */
			reg = < 0x3ff4f000 0x1000 >;        /* in zephyr/dts/xtensa/espressif/esp32/esp32_common.dtsi:361 */
			interrupts = < 0x20 0x0 0x0 >,
			             < 0x20 0x0 0x0 >;      /* in zephyr/dts/xtensa/espressif/esp32/esp32_common.dtsi:362 */
			interrupt-names = "rx",
			                  "tx";             /* in zephyr/dts/xtensa/espressif/esp32/esp32_common.dtsi:364 */
			interrupt-parent = < &intc >;       /* in zephyr/dts/xtensa/espressif/esp32/esp32_common.dtsi:365 */
			clocks = < &clock 0x6 >;            /* in zephyr/dts/xtensa/espressif/esp32/esp32_common.dtsi:366 */
			unit = < 0x0 >;                     /* in zephyr/dts/xtensa/espressif/esp32/esp32_common.dtsi:367 */
			status = "disabled";                /* in zephyr/dts/xtensa/espressif/esp32/esp32_common.dtsi:368 */
		};

		/* node '/soc/i2s@3ff6d000' defined in zephyr/dts/xtensa/espressif/esp32/esp32_common.dtsi:371 */
		i2s1: i2s@3ff6d000 {
			compatible = "espressif,esp32-i2s"; /* in zephyr/dts/xtensa/espressif/esp32/esp32_common.dtsi:372 */
			#address-cells = < 0x1 >;           /* in zephyr/dts/xtensa/espressif/esp32/esp32_common.dtsi:373 */
			#size-cells = < 0x0 >;              /* in zephyr/dts/xtensa/espressif/esp32/esp32_common.dtsi:374 */
			reg = < 0x3ff6d000 0x1000 >;        /* in zephyr/dts/xtensa/espressif/esp32/esp32_common.dtsi:375 */
			interrupts = < 0x21 0x0 0x0 >,
			             < 0x21 0x0 0x0 >;      /* in zephyr/dts/xtensa/espressif/esp32/esp32_common.dtsi:376 */
			interrupt-names = "rx",
			                  "tx";             /* in zephyr/dts/xtensa/espressif/esp32/esp32_common.dtsi:378 */
			interrupt-parent = < &intc >;       /* in zephyr/dts/xtensa/espressif/esp32/esp32_common.dtsi:379 */
			clocks = < &clock 0x7 >;            /* in zephyr/dts/xtensa/espressif/esp32/esp32_common.dtsi:380 */
			unit = < 0x1 >;                     /* in zephyr/dts/xtensa/espressif/esp32/esp32_common.dtsi:381 */
			status = "disabled";                /* in zephyr/dts/xtensa/espressif/esp32/esp32_common.dtsi:382 */
		};

		/* node '/soc/trng@3ff75144' defined in zephyr/dts/xtensa/espressif/esp32/esp32_common.dtsi:385 */
		trng0: trng@3ff75144 {
			compatible = "espressif,esp32-trng"; /* in zephyr/dts/xtensa/espressif/esp32/esp32_common.dtsi:386 */
			reg = < 0x3ff75144 0x4 >;            /* in zephyr/dts/xtensa/espressif/esp32/esp32_common.dtsi:387 */
			clocks = < &clock 0x18 >;            /* in zephyr/dts/xtensa/espressif/esp32/esp32_common.dtsi:388 */
			status = "okay";                     /* in zephyr/boards/m5stack/m5stack_core2/m5stack_core2_procpu.dts:249 */
		};

		/* node '/soc/watchdog@3ff5f048' defined in zephyr/dts/xtensa/espressif/esp32/esp32_common.dtsi:392 */
		wdt0: watchdog@3ff5f048 {
			compatible = "espressif,esp32-watchdog"; /* in zephyr/dts/xtensa/espressif/esp32/esp32_common.dtsi:393 */
			reg = < 0x3ff5f048 0x20 >;               /* in zephyr/dts/xtensa/espressif/esp32/esp32_common.dtsi:394 */
			interrupts = < 0x10 0x0 0x0 >;           /* in zephyr/dts/xtensa/espressif/esp32/esp32_common.dtsi:395 */
			interrupt-parent = < &intc >;            /* in zephyr/dts/xtensa/espressif/esp32/esp32_common.dtsi:396 */
			clocks = < &clock 0x8 >;                 /* in zephyr/dts/xtensa/espressif/esp32/esp32_common.dtsi:397 */
			status = "okay";                         /* in zephyr/dts/xtensa/espressif/esp32/esp32_common.dtsi:398 */
		};

		/* node '/soc/watchdog@3ff60048' defined in zephyr/dts/xtensa/espressif/esp32/esp32_common.dtsi:401 */
		wdt1: watchdog@3ff60048 {
			compatible = "espressif,esp32-watchdog"; /* in zephyr/dts/xtensa/espressif/esp32/esp32_common.dtsi:402 */
			reg = < 0x3ff60048 0x20 >;               /* in zephyr/dts/xtensa/espressif/esp32/esp32_common.dtsi:403 */
			interrupts = < 0x14 0x0 0x0 >;           /* in zephyr/dts/xtensa/espressif/esp32/esp32_common.dtsi:404 */
			interrupt-parent = < &intc >;            /* in zephyr/dts/xtensa/espressif/esp32/esp32_common.dtsi:405 */
			clocks = < &clock 0x9 >;                 /* in zephyr/dts/xtensa/espressif/esp32/esp32_common.dtsi:406 */
			status = "disabled";                     /* in zephyr/dts/xtensa/espressif/esp32/esp32_common.dtsi:407 */
		};

		/* node '/soc/spi@3ff64000' defined in zephyr/dts/xtensa/espressif/esp32/esp32_common.dtsi:410 */
		spi2: spi@3ff64000 {
			compatible = "espressif,esp32-spi"; /* in zephyr/dts/xtensa/espressif/esp32/esp32_common.dtsi:411 */
			reg = < 0x3ff64000 0x1000 >;        /* in zephyr/dts/xtensa/espressif/esp32/esp32_common.dtsi:412 */
			interrupts = < 0x1e 0x0 0x0 >;      /* in zephyr/dts/xtensa/espressif/esp32/esp32_common.dtsi:413 */
			interrupt-parent = < &intc >;       /* in zephyr/dts/xtensa/espressif/esp32/esp32_common.dtsi:414 */
			clocks = < &clock 0x11 >;           /* in zephyr/dts/xtensa/espressif/esp32/esp32_common.dtsi:415 */
			dma-clk = < 0x13 >;                 /* in zephyr/dts/xtensa/espressif/esp32/esp32_common.dtsi:416 */
			dma-host = < 0x0 >;                 /* in zephyr/dts/xtensa/espressif/esp32/esp32_common.dtsi:417 */
			status = "disabled";                /* in zephyr/dts/xtensa/espressif/esp32/esp32_common.dtsi:418 */
		};

		/* node '/soc/spi@3ff65000' defined in zephyr/dts/xtensa/espressif/esp32/esp32_common.dtsi:421 */
		spi3: m5stack_mbus_spi: spi@3ff65000 {
			compatible = "espressif,esp32-spi"; /* in zephyr/dts/xtensa/espressif/esp32/esp32_common.dtsi:422 */
			reg = < 0x3ff65000 0x1000 >;        /* in zephyr/dts/xtensa/espressif/esp32/esp32_common.dtsi:423 */
			interrupts = < 0x1f 0x0 0x0 >;      /* in zephyr/dts/xtensa/espressif/esp32/esp32_common.dtsi:424 */
			interrupt-parent = < &intc >;       /* in zephyr/dts/xtensa/espressif/esp32/esp32_common.dtsi:425 */
			clocks = < &clock 0x12 >;           /* in zephyr/dts/xtensa/espressif/esp32/esp32_common.dtsi:426 */
			dma-clk = < 0x13 >;                 /* in zephyr/dts/xtensa/espressif/esp32/esp32_common.dtsi:427 */
			dma-host = < 0x1 >;                 /* in zephyr/dts/xtensa/espressif/esp32/esp32_common.dtsi:428 */
			#address-cells = < 0x1 >;           /* in zephyr/boards/m5stack/m5stack_core2/m5stack_core2_procpu.dts:208 */
			#size-cells = < 0x0 >;              /* in zephyr/boards/m5stack/m5stack_core2/m5stack_core2_procpu.dts:209 */
			status = "okay";                    /* in zephyr/boards/m5stack/m5stack_core2/m5stack_core2_procpu.dts:210 */
			pinctrl-0 = < &spim3_default >;     /* in zephyr/boards/m5stack/m5stack_core2/m5stack_core2_procpu.dts:211 */
			pinctrl-names = "default";          /* in zephyr/boards/m5stack/m5stack_core2/m5stack_core2_procpu.dts:212 */
			dma-enabled;                        /* in zephyr/boards/m5stack/m5stack_core2/m5stack_core2_procpu.dts:213 */
			clock-frequency = < 0x1312d00 >;    /* in zephyr/boards/m5stack/m5stack_core2/m5stack_core2_procpu.dts:214 */
			cs-gpios = < &gpio0 0x5 0x1 >,
			           < &gpio0 0x4 0x1 >;      /* in zephyr/boards/m5stack/m5stack_core2/m5stack_core2_procpu.dts:215 */
			phandle = < 0x11 >;                 /* in zephyr/boards/m5stack/m5stack_core2/m5stack_core2_procpu.dts:61 */

			/* node '/soc/spi@3ff65000/sd@1' defined in zephyr/boards/m5stack/m5stack_core2/m5stack_core2_procpu.dts:218 */
			sd0: sd@1 {
				compatible = "zephyr,sdhc-spi-slot"; /* in zephyr/boards/m5stack/m5stack_core2/m5stack_core2_procpu.dts:219 */
				reg = < 0x1 >;                       /* in zephyr/boards/m5stack/m5stack_core2/m5stack_core2_procpu.dts:220 */
				status = "okay";                     /* in zephyr/boards/m5stack/m5stack_core2/m5stack_core2_procpu.dts:221 */
				spi-max-frequency = < 0x1312d00 >;   /* in zephyr/boards/m5stack/m5stack_core2/m5stack_core2_procpu.dts:222 */

				/* node '/soc/spi@3ff65000/sd@1/mmc' defined in zephyr/boards/m5stack/m5stack_core2/m5stack_core2_procpu.dts:224 */
				mmc {
					compatible = "zephyr,sdmmc-disk"; /* in zephyr/boards/m5stack/m5stack_core2/m5stack_core2_procpu.dts:225 */
					disk-name = "SD";                 /* in zephyr/boards/m5stack/m5stack_core2/m5stack_core2_procpu.dts:226 */
					status = "okay";                  /* in zephyr/boards/m5stack/m5stack_core2/m5stack_core2_procpu.dts:227 */
				};
			};
		};

		/* node '/soc/can@3ff6b000' defined in zephyr/dts/xtensa/espressif/esp32/esp32_common.dtsi:432 */
		twai: can@3ff6b000 {
			compatible = "espressif,esp32-twai"; /* in zephyr/dts/xtensa/espressif/esp32/esp32_common.dtsi:433 */
			reg = < 0x3ff6b000 0x1000 >;         /* in zephyr/dts/xtensa/espressif/esp32/esp32_common.dtsi:434 */
			interrupts = < 0x2d 0x0 0x0 >;       /* in zephyr/dts/xtensa/espressif/esp32/esp32_common.dtsi:435 */
			interrupt-parent = < &intc >;        /* in zephyr/dts/xtensa/espressif/esp32/esp32_common.dtsi:436 */
			clocks = < &clock 0x16 >;            /* in zephyr/dts/xtensa/espressif/esp32/esp32_common.dtsi:437 */
			status = "disabled";                 /* in zephyr/dts/xtensa/espressif/esp32/esp32_common.dtsi:438 */
		};

		/* node '/soc/counter@3ff5f000' defined in zephyr/dts/xtensa/espressif/esp32/esp32_common.dtsi:441 */
		timer0: counter@3ff5f000 {
			compatible = "espressif,esp32-timer"; /* in zephyr/dts/xtensa/espressif/esp32/esp32_common.dtsi:442 */
			reg = < 0x3ff5f000 0x1000 >;          /* in zephyr/dts/xtensa/espressif/esp32/esp32_common.dtsi:443 */
			clocks = < &clock 0x8 >;              /* in zephyr/dts/xtensa/espressif/esp32/esp32_common.dtsi:444 */
			group = < 0x0 >;                      /* in zephyr/dts/xtensa/espressif/esp32/esp32_common.dtsi:445 */
			index = < 0x0 >;                      /* in zephyr/dts/xtensa/espressif/esp32/esp32_common.dtsi:446 */
			interrupts = < 0xe 0x0 0x0 >;         /* in zephyr/dts/xtensa/espressif/esp32/esp32_common.dtsi:447 */
			interrupt-parent = < &intc >;         /* in zephyr/dts/xtensa/espressif/esp32/esp32_common.dtsi:448 */
			status = "okay";                      /* in zephyr/boards/m5stack/m5stack_core2/m5stack_core2_procpu.dts:233 */

			/* node '/soc/counter@3ff5f000/counter' defined in zephyr/dts/xtensa/espressif/esp32/esp32_common.dtsi:451 */
			counter {
				compatible = "espressif,esp32-counter"; /* in zephyr/dts/xtensa/espressif/esp32/esp32_common.dtsi:452 */
				status = "disabled";                    /* in zephyr/dts/xtensa/espressif/esp32/esp32_common.dtsi:453 */
			};
		};

		/* node '/soc/counter@3ff5f024' defined in zephyr/dts/xtensa/espressif/esp32/esp32_common.dtsi:457 */
		timer1: counter@3ff5f024 {
			compatible = "espressif,esp32-timer"; /* in zephyr/dts/xtensa/espressif/esp32/esp32_common.dtsi:458 */
			reg = < 0x3ff5f024 0x1000 >;          /* in zephyr/dts/xtensa/espressif/esp32/esp32_common.dtsi:459 */
			clocks = < &clock 0x8 >;              /* in zephyr/dts/xtensa/espressif/esp32/esp32_common.dtsi:460 */
			group = < 0x0 >;                      /* in zephyr/dts/xtensa/espressif/esp32/esp32_common.dtsi:461 */
			index = < 0x1 >;                      /* in zephyr/dts/xtensa/espressif/esp32/esp32_common.dtsi:462 */
			interrupts = < 0xf 0x0 0x0 >;         /* in zephyr/dts/xtensa/espressif/esp32/esp32_common.dtsi:463 */
			interrupt-parent = < &intc >;         /* in zephyr/dts/xtensa/espressif/esp32/esp32_common.dtsi:464 */
			status = "okay";                      /* in zephyr/boards/m5stack/m5stack_core2/m5stack_core2_procpu.dts:237 */

			/* node '/soc/counter@3ff5f024/counter' defined in zephyr/dts/xtensa/espressif/esp32/esp32_common.dtsi:467 */
			counter {
				compatible = "espressif,esp32-counter"; /* in zephyr/dts/xtensa/espressif/esp32/esp32_common.dtsi:468 */
				status = "disabled";                    /* in zephyr/dts/xtensa/espressif/esp32/esp32_common.dtsi:469 */
			};
		};

		/* node '/soc/counter@3ff60000' defined in zephyr/dts/xtensa/espressif/esp32/esp32_common.dtsi:473 */
		timer2: counter@3ff60000 {
			compatible = "espressif,esp32-timer"; /* in zephyr/dts/xtensa/espressif/esp32/esp32_common.dtsi:474 */
			reg = < 0x3ff60000 0x1000 >;          /* in zephyr/dts/xtensa/espressif/esp32/esp32_common.dtsi:475 */
			clocks = < &clock 0x9 >;              /* in zephyr/dts/xtensa/espressif/esp32/esp32_common.dtsi:476 */
			group = < 0x1 >;                      /* in zephyr/dts/xtensa/espressif/esp32/esp32_common.dtsi:477 */
			index = < 0x0 >;                      /* in zephyr/dts/xtensa/espressif/esp32/esp32_common.dtsi:478 */
			interrupts = < 0x12 0x0 0x0 >;        /* in zephyr/dts/xtensa/espressif/esp32/esp32_common.dtsi:479 */
			interrupt-parent = < &intc >;         /* in zephyr/dts/xtensa/espressif/esp32/esp32_common.dtsi:480 */
			status = "okay";                      /* in zephyr/boards/m5stack/m5stack_core2/m5stack_core2_procpu.dts:241 */

			/* node '/soc/counter@3ff60000/counter' defined in zephyr/dts/xtensa/espressif/esp32/esp32_common.dtsi:483 */
			counter {
				compatible = "espressif,esp32-counter"; /* in zephyr/dts/xtensa/espressif/esp32/esp32_common.dtsi:484 */
				status = "disabled";                    /* in zephyr/dts/xtensa/espressif/esp32/esp32_common.dtsi:485 */
			};
		};

		/* node '/soc/counter@3ff60024' defined in zephyr/dts/xtensa/espressif/esp32/esp32_common.dtsi:489 */
		timer3: counter@3ff60024 {
			compatible = "espressif,esp32-timer"; /* in zephyr/dts/xtensa/espressif/esp32/esp32_common.dtsi:490 */
			reg = < 0x3ff60024 0x1000 >;          /* in zephyr/dts/xtensa/espressif/esp32/esp32_common.dtsi:491 */
			clocks = < &clock 0x9 >;              /* in zephyr/dts/xtensa/espressif/esp32/esp32_common.dtsi:492 */
			group = < 0x1 >;                      /* in zephyr/dts/xtensa/espressif/esp32/esp32_common.dtsi:493 */
			index = < 0x1 >;                      /* in zephyr/dts/xtensa/espressif/esp32/esp32_common.dtsi:494 */
			interrupts = < 0x13 0x0 0x0 >;        /* in zephyr/dts/xtensa/espressif/esp32/esp32_common.dtsi:495 */
			interrupt-parent = < &intc >;         /* in zephyr/dts/xtensa/espressif/esp32/esp32_common.dtsi:496 */
			status = "okay";                      /* in zephyr/boards/m5stack/m5stack_core2/m5stack_core2_procpu.dts:245 */

			/* node '/soc/counter@3ff60024/counter' defined in zephyr/dts/xtensa/espressif/esp32/esp32_common.dtsi:499 */
			counter {
				compatible = "espressif,esp32-counter"; /* in zephyr/dts/xtensa/espressif/esp32/esp32_common.dtsi:500 */
				status = "disabled";                    /* in zephyr/dts/xtensa/espressif/esp32/esp32_common.dtsi:501 */
			};
		};

		/* node '/soc/dac@3ff48800' defined in zephyr/dts/xtensa/espressif/esp32/esp32_common.dtsi:505 */
		dac: dac@3ff48800 {
			compatible = "espressif,esp32-dac"; /* in zephyr/dts/xtensa/espressif/esp32/esp32_common.dtsi:506 */
			reg = < 0x3ff48800 0x100 >;         /* in zephyr/dts/xtensa/espressif/esp32/esp32_common.dtsi:507 */
			interrupts = < 0x2e 0x0 0x0 >;      /* in zephyr/dts/xtensa/espressif/esp32/esp32_common.dtsi:508 */
			interrupt-parent = < &intc >;       /* in zephyr/dts/xtensa/espressif/esp32/esp32_common.dtsi:509 */
			clocks = < &clock 0x21 >;           /* in zephyr/dts/xtensa/espressif/esp32/esp32_common.dtsi:510 */
			#io-channel-cells = < 0x1 >;        /* in zephyr/dts/xtensa/espressif/esp32/esp32_common.dtsi:511 */
			status = "disabled";                /* in zephyr/dts/xtensa/espressif/esp32/esp32_common.dtsi:512 */
		};

		/* node '/soc/adc@3ff48800' defined in zephyr/dts/xtensa/espressif/esp32/esp32_common.dtsi:515 */
		adc0: adc@3ff48800 {
			compatible = "espressif,esp32-adc"; /* in zephyr/dts/xtensa/espressif/esp32/esp32_common.dtsi:516 */
			reg = < 0x3ff48800 0xa >;           /* in zephyr/dts/xtensa/espressif/esp32/esp32_common.dtsi:517 */
			clocks = < &clock 0x21 >;           /* in zephyr/dts/xtensa/espressif/esp32/esp32_common.dtsi:518 */
			interrupt-parent = < &intc >;       /* in zephyr/dts/xtensa/espressif/esp32/esp32_common.dtsi:519 */
			unit = < 0x1 >;                     /* in zephyr/dts/xtensa/espressif/esp32/esp32_common.dtsi:520 */
			channel-count = < 0x8 >;            /* in zephyr/dts/xtensa/espressif/esp32/esp32_common.dtsi:521 */
			#io-channel-cells = < 0x1 >;        /* in zephyr/dts/xtensa/espressif/esp32/esp32_common.dtsi:522 */
			status = "disabled";                /* in zephyr/dts/xtensa/espressif/esp32/esp32_common.dtsi:523 */
		};

		/* node '/soc/adc@3ff48890' defined in zephyr/dts/xtensa/espressif/esp32/esp32_common.dtsi:526 */
		adc1: adc@3ff48890 {
			compatible = "espressif,esp32-adc"; /* in zephyr/dts/xtensa/espressif/esp32/esp32_common.dtsi:527 */
			reg = < 0x3ff48890 0xa >;           /* in zephyr/dts/xtensa/espressif/esp32/esp32_common.dtsi:528 */
			clocks = < &clock 0x21 >;           /* in zephyr/dts/xtensa/espressif/esp32/esp32_common.dtsi:529 */
			unit = < 0x2 >;                     /* in zephyr/dts/xtensa/espressif/esp32/esp32_common.dtsi:530 */
			channel-count = < 0xa >;            /* in zephyr/dts/xtensa/espressif/esp32/esp32_common.dtsi:531 */
			#io-channel-cells = < 0x1 >;        /* in zephyr/dts/xtensa/espressif/esp32/esp32_common.dtsi:532 */
			status = "disabled";                /* in zephyr/dts/xtensa/espressif/esp32/esp32_common.dtsi:533 */
		};

		/* node '/soc/sdhc@3ff68000' defined in zephyr/dts/xtensa/espressif/esp32/esp32_common.dtsi:536 */
		sdhc: sdhc@3ff68000 {
			compatible = "espressif,esp32-sdhc"; /* in zephyr/dts/xtensa/espressif/esp32/esp32_common.dtsi:537 */
			reg = < 0x3ff68000 0x1000 >;         /* in zephyr/dts/xtensa/espressif/esp32/esp32_common.dtsi:538 */
			interrupts = < 0x25 0x0 0x0 >;       /* in zephyr/dts/xtensa/espressif/esp32/esp32_common.dtsi:539 */
			interrupt-parent = < &intc >;        /* in zephyr/dts/xtensa/espressif/esp32/esp32_common.dtsi:540 */
			clocks = < &clock 0x14 >;            /* in zephyr/dts/xtensa/espressif/esp32/esp32_common.dtsi:541 */
			#address-cells = < 0x1 >;            /* in zephyr/dts/xtensa/espressif/esp32/esp32_common.dtsi:542 */
			#size-cells = < 0x0 >;               /* in zephyr/dts/xtensa/espressif/esp32/esp32_common.dtsi:543 */

			/* node '/soc/sdhc@3ff68000/sdhc@0' defined in zephyr/dts/xtensa/espressif/esp32/esp32_common.dtsi:545 */
			sdhc0: sdhc@0 {
				compatible = "espressif,esp32-sdhc-slot"; /* in zephyr/dts/xtensa/espressif/esp32/esp32_common.dtsi:546 */
				reg = < 0x0 >;                            /* in zephyr/dts/xtensa/espressif/esp32/esp32_common.dtsi:547 */
				status = "disabled";                      /* in zephyr/dts/xtensa/espressif/esp32/esp32_common.dtsi:548 */
			};

			/* node '/soc/sdhc@3ff68000/sdhc@1' defined in zephyr/dts/xtensa/espressif/esp32/esp32_common.dtsi:551 */
			sdhc1: sdhc@1 {
				compatible = "espressif,esp32-sdhc-slot"; /* in zephyr/dts/xtensa/espressif/esp32/esp32_common.dtsi:552 */
				reg = < 0x1 >;                            /* in zephyr/dts/xtensa/espressif/esp32/esp32_common.dtsi:553 */
				status = "disabled";                      /* in zephyr/dts/xtensa/espressif/esp32/esp32_common.dtsi:554 */
			};
		};

		/* node '/soc/sha@3ff03000' defined in zephyr/dts/xtensa/espressif/esp32/esp32_common.dtsi:558 */
		sha: sha@3ff03000 {
			compatible = "espressif,esp32-sha"; /* in zephyr/dts/xtensa/espressif/esp32/esp32_common.dtsi:559 */
			reg = < 0x3ff03000 0x100 >;         /* in zephyr/dts/xtensa/espressif/esp32/esp32_common.dtsi:560 */
			clocks = < &clock 0x1f >;           /* in zephyr/dts/xtensa/espressif/esp32/esp32_common.dtsi:561 */
			status = "okay";                    /* in zephyr/dts/xtensa/espressif/esp32/esp32_common.dtsi:562 */
		};

		/* node '/soc/aes@3ff01000' defined in zephyr/dts/xtensa/espressif/esp32/esp32_common.dtsi:565 */
		aes: aes@3ff01000 {
			compatible = "espressif,esp32-aes"; /* in zephyr/dts/xtensa/espressif/esp32/esp32_common.dtsi:566 */
			reg = < 0x3ff01000 0x1000 >;        /* in zephyr/dts/xtensa/espressif/esp32/esp32_common.dtsi:567 */
			clocks = < &clock 0x1e >;           /* in zephyr/dts/xtensa/espressif/esp32/esp32_common.dtsi:568 */
			status = "okay";                    /* in zephyr/dts/xtensa/espressif/esp32/esp32_common.dtsi:569 */
		};
	};

	/* node '/cpus' defined in zephyr/dts/xtensa/espressif/esp32/esp32_common.dtsi:26 */
	cpus {
		#address-cells = < 0x1 >; /* in zephyr/dts/xtensa/espressif/esp32/esp32_common.dtsi:27 */
		#size-cells = < 0x0 >;    /* in zephyr/dts/xtensa/espressif/esp32/esp32_common.dtsi:28 */

		/* node '/cpus/cpu@0' defined in zephyr/dts/xtensa/espressif/esp32/esp32_common.dtsi:30 */
		cpu0: cpu@0 {
			device_type = "cpu";                             /* in zephyr/dts/xtensa/espressif/esp32/esp32_common.dtsi:31 */
			compatible = "espressif,xtensa-lx6";             /* in zephyr/dts/xtensa/espressif/esp32/esp32_common.dtsi:32 */
			reg = < 0x0 >;                                   /* in zephyr/dts/xtensa/espressif/esp32/esp32_common.dtsi:33 */
			cpu-power-states = < &light_sleep &deep_sleep >; /* in zephyr/dts/xtensa/espressif/esp32/esp32_common.dtsi:34 */
			clock-source = < 0x1 >;                          /* in zephyr/dts/xtensa/espressif/esp32/esp32_common.dtsi:35 */
			clock-frequency = < 0xe4e1c00 >;                 /* in zephyr/dts/xtensa/espressif/esp32/esp32_common.dtsi:36 */
			xtal-freq = < 0x2625a00 >;                       /* in zephyr/dts/xtensa/espressif/esp32/esp32_common.dtsi:37 */
		};

		/* node '/cpus/cpu@1' defined in zephyr/dts/xtensa/espressif/esp32/esp32_common.dtsi:40 */
		cpu1: cpu@1 {
			device_type = "cpu";                 /* in zephyr/dts/xtensa/espressif/esp32/esp32_common.dtsi:41 */
			compatible = "espressif,xtensa-lx6"; /* in zephyr/dts/xtensa/espressif/esp32/esp32_common.dtsi:42 */
			reg = < 0x1 >;                       /* in zephyr/dts/xtensa/espressif/esp32/esp32_common.dtsi:43 */
			clock-source = < 0x1 >;              /* in zephyr/dts/xtensa/espressif/esp32/esp32_common.dtsi:44 */
			clock-frequency = < 0xe4e1c00 >;     /* in zephyr/dts/xtensa/espressif/esp32/esp32_common.dtsi:45 */
			xtal-freq = < 0x2625a00 >;           /* in zephyr/dts/xtensa/espressif/esp32/esp32_common.dtsi:46 */
		};

		/* node '/cpus/power-states' defined in zephyr/dts/xtensa/espressif/esp32/esp32_common.dtsi:49 */
		power-states {

			/* node '/cpus/power-states/light_sleep' defined in zephyr/dts/xtensa/espressif/esp32/esp32_common.dtsi:50 */
			light_sleep: light_sleep {
				compatible = "zephyr,power-state"; /* in zephyr/dts/xtensa/espressif/esp32/esp32_common.dtsi:51 */
				power-state-name = "standby";      /* in zephyr/dts/xtensa/espressif/esp32/esp32_common.dtsi:52 */
				min-residency-us = < 0xc8 >;       /* in zephyr/dts/xtensa/espressif/esp32/esp32_common.dtsi:53 */
				exit-latency-us = < 0x3c >;        /* in zephyr/dts/xtensa/espressif/esp32/esp32_common.dtsi:54 */
				phandle = < 0xd >;                 /* in zephyr/dts/xtensa/espressif/esp32/esp32_common.dtsi:34 */
			};

			/* node '/cpus/power-states/deep_sleep' defined in zephyr/dts/xtensa/espressif/esp32/esp32_common.dtsi:57 */
			deep_sleep: deep_sleep {
				compatible = "zephyr,power-state"; /* in zephyr/dts/xtensa/espressif/esp32/esp32_common.dtsi:58 */
				power-state-name = "soft-off";     /* in zephyr/dts/xtensa/espressif/esp32/esp32_common.dtsi:59 */
				min-residency-us = < 0x7d0 >;      /* in zephyr/dts/xtensa/espressif/esp32/esp32_common.dtsi:60 */
				exit-latency-us = < 0xd4 >;        /* in zephyr/dts/xtensa/espressif/esp32/esp32_common.dtsi:61 */
				phandle = < 0xe >;                 /* in zephyr/dts/xtensa/espressif/esp32/esp32_common.dtsi:34 */
			};
		};
	};

	/* node '/wifi' defined in zephyr/dts/xtensa/espressif/esp32/esp32_common.dtsi:66 */
	wifi: wifi {
		compatible = "espressif,esp32-wifi"; /* in zephyr/dts/xtensa/espressif/esp32/esp32_common.dtsi:67 */
		status = "okay";                     /* in zephyr/boards/m5stack/m5stack_core2/m5stack_core2_procpu.dts:257 */
	};

	/* node '/esp32_bt_hci' defined in zephyr/dts/xtensa/espressif/esp32/esp32_common.dtsi:71 */
	esp32_bt_hci: esp32_bt_hci {
		compatible = "espressif,esp32-bt-hci"; /* in zephyr/dts/xtensa/espressif/esp32/esp32_common.dtsi:72 */
		status = "okay";                       /* in zephyr/boards/m5stack/m5stack_core2/m5stack_core2_procpu.dts:253 */
	};

	/* node '/eth' defined in zephyr/dts/xtensa/espressif/esp32/esp32_common.dtsi:76 */
	eth: eth {
		compatible = "espressif,esp32-eth"; /* in zephyr/dts/xtensa/espressif/esp32/esp32_common.dtsi:77 */
		interrupts = < 0x26 0x0 0x0 >;      /* in zephyr/dts/xtensa/espressif/esp32/esp32_common.dtsi:78 */
		interrupt-parent = < &intc >;       /* in zephyr/dts/xtensa/espressif/esp32/esp32_common.dtsi:79 */
		clocks = < &clock 0x17 >;           /* in zephyr/dts/xtensa/espressif/esp32/esp32_common.dtsi:80 */
		status = "disabled";                /* in zephyr/dts/xtensa/espressif/esp32/esp32_common.dtsi:81 */
	};

	/* node '/mdio' defined in zephyr/dts/xtensa/espressif/esp32/esp32_common.dtsi:84 */
	mdio: mdio {
		compatible = "espressif,esp32-mdio"; /* in zephyr/dts/xtensa/espressif/esp32/esp32_common.dtsi:85 */
		clocks = < &clock 0x17 >;            /* in zephyr/dts/xtensa/espressif/esp32/esp32_common.dtsi:86 */
		status = "disabled";                 /* in zephyr/dts/xtensa/espressif/esp32/esp32_common.dtsi:87 */
		#address-cells = < 0x1 >;            /* in zephyr/dts/xtensa/espressif/esp32/esp32_common.dtsi:88 */
		#size-cells = < 0x0 >;               /* in zephyr/dts/xtensa/espressif/esp32/esp32_common.dtsi:89 */
	};

	/* node '/pin-controller' defined in zephyr/dts/xtensa/espressif/esp32/esp32_common.dtsi:92 */
	pinctrl: pin-controller {
		compatible = "espressif,esp32-pinctrl"; /* in zephyr/dts/xtensa/espressif/esp32/esp32_common.dtsi:93 */
		status = "okay";                        /* in zephyr/dts/xtensa/espressif/esp32/esp32_common.dtsi:94 */

		/* node '/pin-controller/uart0_tx_gpio1' defined in zephyr/boards/m5stack/m5stack_core2/m5stack_core2-pinctrl.dtsi:13 */
		uart0_tx_gpio1: uart0_tx_gpio1 {
			pinmux = < 0x77fc1 >; /* in zephyr/boards/m5stack/m5stack_core2/m5stack_core2-pinctrl.dtsi:14 */
			phandle = < 0x4 >;    /* in zephyr/boards/m5stack/m5stack_core2/m5stack_core2_procpu.dts:97 */
		};

		/* node '/pin-controller/uart0_rx_gpio3' defined in zephyr/boards/m5stack/m5stack_core2/m5stack_core2-pinctrl.dtsi:17 */
		uart0_rx_gpio3: uart0_rx_gpio3 {
			pinmux = < 0xff8383 >; /* in zephyr/boards/m5stack/m5stack_core2/m5stack_core2-pinctrl.dtsi:18 */
			bias-pull-up;          /* in zephyr/boards/m5stack/m5stack_core2/m5stack_core2-pinctrl.dtsi:19 */
			phandle = < 0x5 >;     /* in zephyr/boards/m5stack/m5stack_core2/m5stack_core2_procpu.dts:97 */
		};

		/* node '/pin-controller/uart1_rx_gpio33' defined in zephyr/boards/m5stack/m5stack_core2/m5stack_core2-pinctrl.dtsi:22 */
		uart1_rx_gpio33: uart1_rx_gpio33 {
			pinmux = < 0xff8461 >; /* in zephyr/boards/m5stack/m5stack_core2/m5stack_core2-pinctrl.dtsi:23 */
			phandle = < 0x6 >;     /* in zephyr/boards/m5stack/m5stack_core2/m5stack_core2_procpu.dts:104 */
		};

		/* node '/pin-controller/uart2_rx_gpio13' defined in zephyr/boards/m5stack/m5stack_core2/m5stack_core2-pinctrl.dtsi:26 */
		uart2_rx_gpio13: uart2_rx_gpio13 {
			pinmux = < 0xffb18d >; /* in zephyr/boards/m5stack/m5stack_core2/m5stack_core2-pinctrl.dtsi:27 */
		};

		/* node '/pin-controller/uart2_rx_gpio14' defined in zephyr/boards/m5stack/m5stack_core2/m5stack_core2-pinctrl.dtsi:30 */
		uart2_tx_gpio14: uart2_rx_gpio14 {
			pinmux = < 0x637fce >; /* in zephyr/boards/m5stack/m5stack_core2/m5stack_core2-pinctrl.dtsi:31 */
		};

		/* node '/pin-controller/uart1_tx_gpio32' defined in zephyr/boards/m5stack/m5stack_core2/m5stack_core2-pinctrl.dtsi:34 */
		uart1_tx_gpio32: uart1_tx_gpio32 {
			pinmux = < 0x8ffe0 >; /* in zephyr/boards/m5stack/m5stack_core2/m5stack_core2-pinctrl.dtsi:35 */
			phandle = < 0x7 >;    /* in zephyr/boards/m5stack/m5stack_core2/m5stack_core2_procpu.dts:104 */
		};

		/* node '/pin-controller/spim3_default' defined in zephyr/boards/m5stack/m5stack_core2/m5stack_core2-pinctrl.dtsi:38 */
		spim3_default: spim3_default {
			phandle = < 0xc >; /* in zephyr/boards/m5stack/m5stack_core2/m5stack_core2_procpu.dts:211 */

			/* node '/pin-controller/spim3_default/group1' defined in zephyr/boards/m5stack/m5stack_core2/m5stack_core2-pinctrl.dtsi:39 */
			group1 {
				pinmux = < 0xff9026 >,
				         < 0x1fffd2 >; /* in zephyr/boards/m5stack/m5stack_core2/m5stack_core2-pinctrl.dtsi:40 */
			};

			/* node '/pin-controller/spim3_default/group2' defined in zephyr/boards/m5stack/m5stack_core2/m5stack_core2-pinctrl.dtsi:44 */
			group2 {
				pinmux = < 0x20ffd7 >; /* in zephyr/boards/m5stack/m5stack_core2/m5stack_core2-pinctrl.dtsi:45 */
				output-low;            /* in zephyr/boards/m5stack/m5stack_core2/m5stack_core2-pinctrl.dtsi:46 */
			};
		};

		/* node '/pin-controller/i2c0_default' defined in zephyr/boards/m5stack/m5stack_core2/m5stack_core2-pinctrl.dtsi:50 */
		i2c0_default: i2c0_default {
			phandle = < 0xa >; /* in zephyr/boards/m5stack/m5stack_core2/m5stack_core2_procpu.dts:121 */

			/* node '/pin-controller/i2c0_default/group1' defined in zephyr/boards/m5stack/m5stack_core2/m5stack_core2-pinctrl.dtsi:51 */
			group1 {
				pinmux = < 0xf0795 >,
				         < 0xe8756 >; /* in zephyr/boards/m5stack/m5stack_core2/m5stack_core2-pinctrl.dtsi:52 */
				drive-open-drain;     /* in zephyr/boards/m5stack/m5stack_core2/m5stack_core2-pinctrl.dtsi:54 */
				output-high;          /* in zephyr/boards/m5stack/m5stack_core2/m5stack_core2-pinctrl.dtsi:55 */
			};
		};

		/* node '/pin-controller/i2c1_default' defined in zephyr/boards/m5stack/m5stack_core2/m5stack_core2-pinctrl.dtsi:59 */
		i2c1_default: i2c1_default {
			phandle = < 0xb >; /* in zephyr/boards/m5stack/m5stack_core2/m5stack_core2_procpu.dts:203 */

			/* node '/pin-controller/i2c1_default/group1' defined in zephyr/boards/m5stack/m5stack_core2/m5stack_core2-pinctrl.dtsi:60 */
			group1 {
				pinmux = < 0x301820 >,
				         < 0x2f97e1 >; /* in zephyr/boards/m5stack/m5stack_core2/m5stack_core2-pinctrl.dtsi:61 */
				drive-open-drain;      /* in zephyr/boards/m5stack/m5stack_core2/m5stack_core2-pinctrl.dtsi:63 */
				output-high;           /* in zephyr/boards/m5stack/m5stack_core2/m5stack_core2-pinctrl.dtsi:64 */
			};
		};
	};

	/* node '/clock' defined in zephyr/dts/xtensa/espressif/esp32/esp32_common.dtsi:97 */
	clock: clock {
		compatible = "espressif,esp32-clock"; /* in zephyr/dts/xtensa/espressif/esp32/esp32_common.dtsi:98 */
		fast-clk-src = < 0x1 >;               /* in zephyr/dts/xtensa/espressif/esp32/esp32_common.dtsi:99 */
		slow-clk-src = < 0x0 >;               /* in zephyr/dts/xtensa/espressif/esp32/esp32_common.dtsi:100 */
		#clock-cells = < 0x1 >;               /* in zephyr/dts/xtensa/espressif/esp32/esp32_common.dtsi:101 */
		status = "okay";                      /* in zephyr/dts/xtensa/espressif/esp32/esp32_common.dtsi:102 */
		phandle = < 0x3 >;                    /* in zephyr/dts/xtensa/espressif/esp32/esp32_common.dtsi:192 */
	};

	/* node '/grove_header' defined in zephyr/boards/m5stack/m5stack_core2/grove_connectors.dtsi:8 */
	grove_header: grove_header {
		compatible = "grove-header";               /* in zephyr/boards/m5stack/m5stack_core2/grove_connectors.dtsi:9 */
		#gpio-cells = < 0x2 >;                     /* in zephyr/boards/m5stack/m5stack_core2/grove_connectors.dtsi:10 */
		gpio-map-mask = < 0xffffffff 0xffffffc0 >; /* in zephyr/boards/m5stack/m5stack_core2/grove_connectors.dtsi:11 */
		gpio-map-pass-thru = < 0x0 0x3f >;         /* in zephyr/boards/m5stack/m5stack_core2/grove_connectors.dtsi:12 */
		gpio-map = < 0x0 0x0 &gpio1 0x1 0x0 >,
		           < 0x1 0x0 &gpio1 0x0 0x0 >;     /* in zephyr/boards/m5stack/m5stack_core2/grove_connectors.dtsi:13 */
	};

	/* node '/m5stack_mbus_connector' defined in zephyr/boards/m5stack/m5stack_core2/m5stack_mbus_connectors.dtsi:7 */
	m5stack_mbus_header: m5stack_mbus_connector {
		compatible = "m5stack,mbus-header";        /* in zephyr/boards/m5stack/m5stack_core2/m5stack_mbus_connectors.dtsi:8 */
		#gpio-cells = < 0x2 >;                     /* in zephyr/boards/m5stack/m5stack_core2/m5stack_mbus_connectors.dtsi:9 */
		gpio-map-mask = < 0xffffffff 0xffffffc0 >; /* in zephyr/boards/m5stack/m5stack_core2/m5stack_mbus_connectors.dtsi:10 */
		gpio-map-pass-thru = < 0x0 0x3f >;         /* in zephyr/boards/m5stack/m5stack_core2/m5stack_mbus_connectors.dtsi:11 */
		gpio-map = < 0x1 0x0 &gpio1 0x4 0x0 >,
		           < 0x3 0x0 &gpio1 0x5 0x0 >,
		           < 0x6 0x0 &gpio0 0x17 0x0 >,
		           < 0x7 0x0 &gpio0 0x19 0x0 >,
		           < 0x8 0x0 &gpio1 0x7 0x0 >,
		           < 0x9 0x0 &gpio0 0x1a 0x0 >,
		           < 0xa 0x0 &gpio0 0x12 0x0 >,
		           < 0xc 0x0 &gpio0 0x3 0x0 >,
		           < 0xd 0x0 &gpio0 0x1 0x0 >,
		           < 0xe 0x0 &gpio0 0xd 0x0 >,
		           < 0xf 0x0 &gpio0 0xe 0x0 >,
		           < 0x10 0x0 &gpio0 0x15 0x0 >,
		           < 0x11 0x0 &gpio0 0x16 0x0 >,
		           < 0x12 0x0 &gpio1 0x0 0x0 >,
		           < 0x13 0x0 &gpio1 0x1 0x0 >,
		           < 0x14 0x0 &gpio0 0x1b 0x0 >,
		           < 0x15 0x0 &gpio0 0x13 0x0 >,
		           < 0x16 0x0 &gpio0 0x2 0x0 >,
		           < 0x17 0x0 &gpio0 0x0 0x0 >,
		           < 0x19 0x0 &gpio1 0x3 0x0 >;    /* in zephyr/boards/m5stack/m5stack_core2/m5stack_mbus_connectors.dtsi:12 */
	};

	/* node '/leds' defined in zephyr/boards/m5stack/m5stack_core2/m5stack_core2_procpu.dts:42 */
	leds {
		compatible = "gpio-leds"; /* in zephyr/boards/m5stack/m5stack_core2/m5stack_core2_procpu.dts:43 */

		/* node '/leds/led_pwr' defined in zephyr/boards/m5stack/m5stack_core2/m5stack_core2_procpu.dts:45 */
		led_pwr: led_pwr {
			gpios = < &axp192_gpio 0x1 0x7 >; /* in zephyr/boards/m5stack/m5stack_core2/m5stack_core2_procpu.dts:46 */
			label = "Power LED";              /* in zephyr/boards/m5stack/m5stack_core2/m5stack_core2_procpu.dts:47 */
		};
	};

	/* node '/lvgl_pointer' defined in zephyr/boards/m5stack/m5stack_core2/m5stack_core2_procpu.dts:51 */
	lvgl_pointer {
		compatible = "zephyr,lvgl-pointer-input"; /* in zephyr/boards/m5stack/m5stack_core2/m5stack_core2_procpu.dts:52 */
		input = < &ft5336_touch >;                /* in zephyr/boards/m5stack/m5stack_core2/m5stack_core2_procpu.dts:53 */
		swap-xy;                                  /* in zephyr/boards/m5stack/m5stack_core2/m5stack_core2_procpu.dts:54 */
	};

	/* node '/mipi_dbi' defined in zephyr/boards/m5stack/m5stack_core2/m5stack_core2_procpu.dts:57 */
	mipi_dbi {
		compatible = "zephyr,mipi-dbi-spi";     /* in zephyr/boards/m5stack/m5stack_core2/m5stack_core2_procpu.dts:58 */
		dc-gpios = < &gpio0 0xf 0x0 >;          /* in zephyr/boards/m5stack/m5stack_core2/m5stack_core2_procpu.dts:59 */
		reset-gpios = < &axp192_gpio 0x4 0x7 >; /* in zephyr/boards/m5stack/m5stack_core2/m5stack_core2_procpu.dts:60 */
		spi-dev = < &spi3 >;                    /* in zephyr/boards/m5stack/m5stack_core2/m5stack_core2_procpu.dts:61 */
		write-only;                             /* in zephyr/boards/m5stack/m5stack_core2/m5stack_core2_procpu.dts:62 */
		#address-cells = < 0x1 >;               /* in zephyr/boards/m5stack/m5stack_core2/m5stack_core2_procpu.dts:63 */
		#size-cells = < 0x0 >;                  /* in zephyr/boards/m5stack/m5stack_core2/m5stack_core2_procpu.dts:64 */

		/* node '/mipi_dbi/ili9342c@0' defined in zephyr/boards/m5stack/m5stack_core2/m5stack_core2_procpu.dts:66 */
		ili9342c: ili9342c@0 {
			compatible = "ilitek,ili9342c";     /* in zephyr/boards/m5stack/m5stack_core2/m5stack_core2_procpu.dts:67 */
			mipi-max-frequency = < 0x1c9c380 >; /* in zephyr/boards/m5stack/m5stack_core2/m5stack_core2_procpu.dts:68 */
			reg = < 0x0 >;                      /* in zephyr/boards/m5stack/m5stack_core2/m5stack_core2_procpu.dts:69 */
			vin-supply = < &lcd_bg >;           /* in zephyr/boards/m5stack/m5stack_core2/m5stack_core2_procpu.dts:70 */
			pixel-format = < 0x0 >;             /* in zephyr/boards/m5stack/m5stack_core2/m5stack_core2_procpu.dts:71 */
			display-inversion;                  /* in zephyr/boards/m5stack/m5stack_core2/m5stack_core2_procpu.dts:72 */
			width = < 0x140 >;                  /* in zephyr/boards/m5stack/m5stack_core2/m5stack_core2_procpu.dts:73 */
			height = < 0xf0 >;                  /* in zephyr/boards/m5stack/m5stack_core2/m5stack_core2_procpu.dts:74 */
			rotation = < 0x0 >;                 /* in zephyr/boards/m5stack/m5stack_core2/m5stack_core2_procpu.dts:75 */
		};
	};

	/* node '/bus_5v' defined in zephyr/boards/m5stack/m5stack_core2/m5stack_core2_procpu.dts:79 */
	bus_5v: bus_5v {
		compatible = "regulator-fixed";          /* in zephyr/boards/m5stack/m5stack_core2/m5stack_core2_procpu.dts:80 */
		regulator-name = "bus_5v";               /* in zephyr/boards/m5stack/m5stack_core2/m5stack_core2_procpu.dts:81 */
		enable-gpios = < &axp192_gpio 0x5 0x0 >; /* in zephyr/boards/m5stack/m5stack_core2/m5stack_core2_procpu.dts:82 */
	};
};
